VERSION ""

NS_ :

BS_:

BU_: VCU TBOX ACC GW LAS

BO_ 1107 ACC_NM: 8 ACC
 SG_ ACC_NMSourceAddress : 7|8@0+ (1,0) [0|255] ""  LAS

BO_ 1030 GW_NM: 8 GW
 SG_ GW_NMSourceAddress : 7|8@0+ (1,0) [0|255] ""  LAS

BO_ 1106 LAS_NM: 8 LAS
 SG_ LAS_NMSourceAddress : 7|8@0+ (1,0) [0|255] "" Vector__XXX

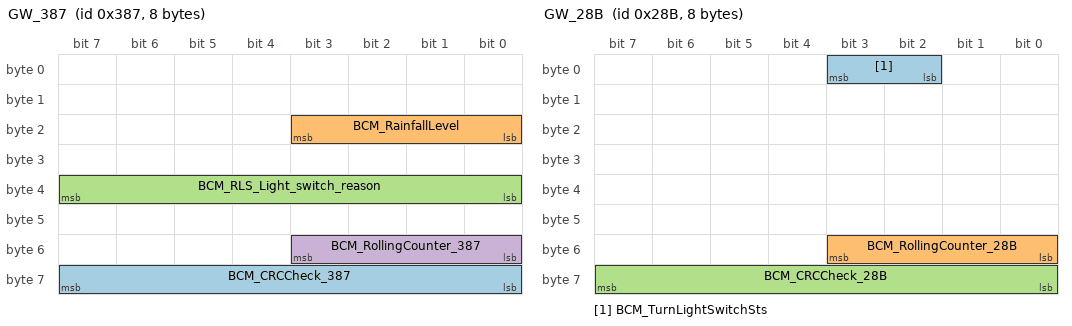
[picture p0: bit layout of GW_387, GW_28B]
BO_ 903 GW_387: 8 GW
 SG_ BCM_CRCCheck_387 : 63|8@0+ (1,0) [0|255] ""  LAS
 SG_ BCM_RainfallLevel : 19|4@0+ (1,0) [0|15] ""  LAS
 SG_ BCM_RLS_Light_switch_reason : 39|8@0+ (1,0) [0|255] ""  LAS
 SG_ BCM_RollingCounter_387 : 51|4@0+ (1,0) [0|15] ""  LAS

BO_ 651 GW_28B: 8 GW
 SG_ BCM_TurnLightSwitchSts : 3|2@0+ (1,0) [0|3] ""  LAS
 SG_ BCM_RollingCounter_28B : 51|4@0+ (1,0) [0|15] ""  LAS
 SG_ BCM_CRCCheck_28B : 63|8@0+ (1,0) [0|255] ""  LAS

BO_ 648 GW_288: 8 GW
 SG_ BcmAutHeadLiSts : 16|1@0+ (1,0) [0|1] ""  LAS
 SG_ BcmCrcChk288 : 63|8@0+ (1,0) [0|255] ""  LAS
 SG_ BcmCycCntr288 : 51|4@0+ (1,0) [0|15] ""  LAS
 SG_ BcmDrvrDoorSts : 23|1@0+ (1,0) [0|1] ""  LAS
 SG_ BcmFrntFogLmpSts : 3|2@0+ (1,0) [0|3] ""  LAS
 SG_ BcmFrntWiperSts : 47|2@0+ (1,0) [0|3] ""  LAS
 SG_ BcmHiBeamSts : 5|2@0+ (1,0) [0|3] ""  LAS
 SG_ BcmHoodSts : 18|1@0+ (1,0) [0|1] ""  LAS
 SG_ BcmLeReDoorSts : 21|1@0+ (1,0) [0|1] ""  LAS
 SG_ BcmLiSnsrFlt : 45|1@0+ (1,0) [0|1] ""  LAS
 SG_ BcmLoBeamSts : 7|2@0+ (1,0) [0|3] ""  LAS
 SG_ BcmPassDoorSts : 22|1@0+ (1,0) [0|1] ""  LAS
 SG_ BcmReFoglmpSts : 1|2@0+ (1,0) [0|3] ""  LAS
 SG_ BcmRiReDoorSts : 20|1@0+ (1,0) [0|1] ""  LAS
 SG_ BcmStsRainSnsr : 54|1@0+ (1,0) [0|1] ""  LAS
 SG_ BcmTurnIndcrLe : 15|2@0+ (1,0) [0|3] ""  LAS
 SG_ BcmTurnIndcrRi : 13|2@0+ (1,0) [0|3] ""  LAS
 SG_ BcmEmgyLiSts : 37|2@0+ (1,0) [0|3] ""  LAS

BO_ 1006 GW_3EE: 8 GW
 SG_ GW_SafCertSts : 7|2@0+ (1,0) [0|3] ""  LAS

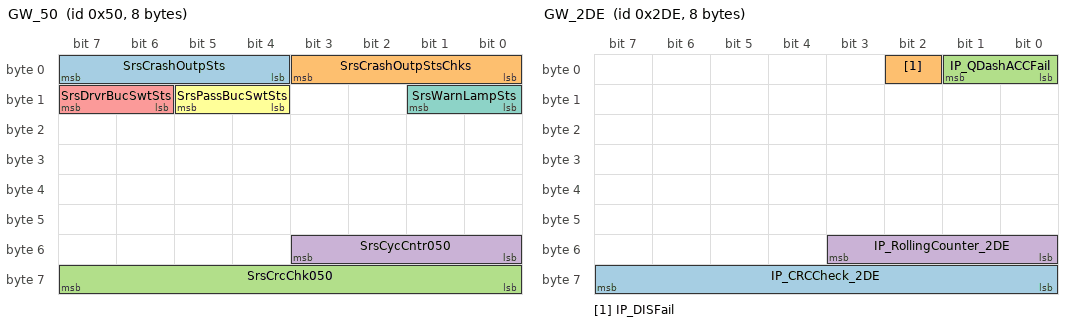
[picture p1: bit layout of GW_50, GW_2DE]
BO_ 80 GW_50: 8 GW
 SG_ SrsCrashOutpSts : 7|4@0+ (1,0) [0|15] ""  LAS
 SG_ SrsCrashOutpStsChks : 3|4@0+ (1,0) [0|15] ""  LAS
 SG_ SrsCrcChk050 : 63|8@0+ (1,0) [0|255] ""  LAS
 SG_ SrsCycCntr050 : 51|4@0+ (1,0) [0|15] ""  LAS
 SG_ SrsDrvrBucSwtSts : 15|2@0+ (1,0) [0|3] ""  LAS
 SG_ SrsPassBucSwtSts : 13|2@0+ (1,0) [0|3] ""  LAS
 SG_ SrsWarnLampSts : 9|2@0+ (1,0) [0|3] ""  LAS

BO_ 759 TBOX_2F7: 64 TBOX
 SG_ TboxLocalTiDate : 20|5@0+ (1,0) [0|31] "day"  LAS
 SG_ TboxLocalTiHr : 28|5@0+ (1,0) [0|31] "hour"  LAS
 SG_ TboxLocalTiMins : 37|6@0+ (1,0) [0|63] "minute"  LAS
 SG_ TboxLocalTiMth : 11|4@0+ (1,0) [0|15] "month"  LAS
 SG_ TboxLocalTiSec : 45|6@0+ (1,0) [0|63] "second"  LAS
 SG_ TboxLocalTiVld : 46|1@0+ (1,0) [0|1] ""  LAS
 SG_ TboxLocalTiYear : 7|8@0+ (1,2000) [2000|2255] "year"  LAS

BO_ 353 VCU_161: 64 VCU
 SG_ VcuSimnEpbSwtSts : 45|2@0+ (1,0) [0|3] ""  LAS
 SG_ VcuSimnEpbSwtStsVld : 46|1@0+ (1,0) [0|1] ""  LAS
 SG_ VCUAccPedShield : 7|1@0+ (1,0) [0|1] ""  LAS
 SG_ VCUShiftPostionValid : 2|1@0+ (1,0) [0|1] ""  LAS
 SG_ VcuAccrMod : 1|3@0+ (1,0) [0|7] ""  LAS
 SG_ VcuAccrPedlPosn : 14|10@0+ (0.1,0) [0|102.3] "%"  LAS
 SG_ VcuAccrPedlPosnVld : 20|1@0+ (1,0) [0|1] ""  LAS
 SG_ VcuCalcnAccrPedlPosn : 18|10@0+ (0.1,0) [0|102.3] "%"  LAS
 SG_ VcuCalcnAccrPedlPosnVld : 24|1@0+ (1,0) [0|1] ""  LAS
 SG_ VcuComFltSts : 39|2@0+ (1,0) [0|3] ""  LAS
 SG_ VcuEnyRecyclMod : 37|7@0+ (1,0) [0|127] ""  LAS
 SG_ VcuGearPosn : 65|3@0+ (1,0) [0|7] ""  LAS
 SG_ VcuOvrdModReq : 78|1@0+ (1,0) [0|1] ""  LAS
 SG_ VcuPtTqLimMax : 87|16@0+ (1,-32768) [-32768|32767] "Nm"  LAS
 SG_ VcuPtTqLimMaxVld : 77|1@0+ (1,0) [0|1] ""  LAS
 SG_ VcuPtTqLimMin : 103|16@0+ (1,-32768) [-32768|32767] "Nm"  LAS
 SG_ VcuPtTqLimMinVld : 76|1@0+ (1,0) [0|1] ""  LAS
 SG_ VcuPtTqReal : 135|16@0+ (1,-32768) [-32768|32767] "Nm"  LAS
 SG_ VcuPtTqRealVld : 75|1@0+ (1,0) [0|1] ""  LAS
 SG_ VcuPtTqReqAvl : 74|2@0+ (1,0) [0|3] ""  LAS
 SG_ VcuRdySts : 151|1@0+ (1,0) [0|1] ""  LAS
 SG_ VcuShiftLvlPosn : 119|4@0+ (1,0) [0|15] ""  LAS
 SG_ VcuVehGearPosnVld : 150|1@0+ (1,0) [0|1] ""  LAS
 SG_ VcuVehWhlReqTq : 159|16@0+ (1,-32768) [-32768|32767] "Nm"  LAS
 SG_ VcuVehWhlReqTqVld : 149|1@0+ (1,0) [0|1] ""  LAS
 SG_ VcuCrcChk161 : 503|16@0+ (1,0) [0|65535] ""  LAS
 SG_ VcuCycCntr161 : 491|4@0+ (1,0) [0|15] ""  LAS

BO_ 680 GW_2A8: 64 GW
 SG_ TmsAcEnvtlT : 39|8@0+ (0.5,-40) [-40|87.5] ""  LAS
 SG_ TmsAcEnvtlTVld : 432|1@0+ (1,0) [0|1] ""  LAS
 SG_ TmsFrntBlowMod : 186|3@0+ (1,0) [0|7] ""  LAS
 SG_ TmsActPwr : 18|11@0+ (0.01,0) [0|20.47] "kW"  LAS

BO_ 943 GW_3AF: 64 GW
 SG_ HU_AccidentProne : 149|2@0+ (1,0) [0|3] ""  LAS
 SG_ HU_AccidentProneDistance : 147|6@0+ (10,0) [0|600] "m"  LAS
 SG_ HU_BridgeDis : 163|6@0+ (10,0) [0|600] "m"  LAS
 SG_ HU_BridgeInfo : 165|2@0+ (1,0) [0|3] ""  LAS
 SG_ HU_CRCCheck_3AF : 255|8@0+ (1,0) [0|255] ""  LAS
 SG_ HU_CRCCheck_3BB : 319|8@0+ (1,0) [0|255] ""  LAS
 SG_ HU_CurveDistance : 229|6@0+ (10,0) [0|600] "m"  LAS
 SG_ HU_EnterCurveInfo : 220|2@0+ (1,0) [0|3] ""  LAS
 SG_ HU_EnterRampInfo : 215|2@0+ (1,0) [0|3] ""  LAS
 SG_ HU_IntervalVelocityDis : 139|6@0+ (10,0) [0|600] "m"  LAS
 SG_ HU_IntervalVelocityInfo : 141|2@0+ (1,0) [0|3] ""  LAS
 SG_ HU_LaneConfluence : 157|2@0+ (1,0) [0|3] ""  LAS
 SG_ HU_LaneConfluenceDis : 155|6@0+ (10,0) [0|600] "m"  LAS
 SG_ HU_LaneType_ID1 : 321|4@0+ (1,0) [0|15] ""  LAS
 SG_ HU_LaneType_ID2 : 333|4@0+ (1,0) [0|15] ""  LAS
 SG_ HU_LaneType_ID3 : 329|4@0+ (1,0) [0|15] ""  LAS
 SG_ HU_LaneType_ID4 : 341|4@0+ (1,0) [0|15] ""  LAS
 SG_ HU_LaneType_ID5 : 337|4@0+ (1,0) [0|15] ""  LAS
 SG_ HU_LaneType_ID6 : 349|4@0+ (1,0) [0|15] ""  LAS
 SG_ HU_NavCountryCode : 199|8@0+ (1,0) [0|255] ""  LAS
 SG_ HU_NavCurrentRoadType : 218|3@0+ (1,0) [0|7] ""  LAS
 SG_ HU_NavSpeedLimit : 207|8@0+ (1,0) [0|255] ""  LAS
 SG_ HU_NavSpeedLimitStatus : 211|2@0+ (1,0) [0|3] ""  LAS
 SG_ HU_NavSpeedLimitType : 231|2@0+ (1,0) [0|3] ""  LAS
 SG_ HU_NavSpeedLimitUnits : 213|2@0+ (1,0) [0|3] ""  LAS
 SG_ HU_NavStatus : 223|1@0+ (1,0) [0|1] ""  LAS
 SG_ HU_RampDistance : 239|10@0+ (10,0) [0|3000] "m"  LAS
 SG_ HU_RampInfo : 209|2@0+ (1,0) [0|3] ""  LAS
 SG_ HU_RollingCounter_3AF : 243|4@0+ (1,0) [0|15] ""  LAS
 SG_ HU_RollingCounter_3BB : 307|4@0+ (1,0) [0|15] ""  LAS
 SG_ HU_ServiceRoad : 183|2@0+ (1,0) [0|3] "m"  LAS
 SG_ HU_ServiceRoadDis : 327|6@0+ (10,0) [0|600] "m"  LAS
 SG_ HU_SlopeGradient : 265|10@0+ (0.1,-51.1) [-51.1|51.1] "%"  LAS
 SG_ HU_SlopeGradient_100m : 135|10@0+ (0.1,-51.1) [-51.1|51.1] "m"  LAS
 SG_ HU_SlopeGradient_10m : 71|10@0+ (0.1,-51.1) [-51.1|51.1] ""  LAS
 SG_ HU_SlopeGradient_20m : 77|10@0+ (0.1,-51.1) [-51.1|51.1] ""  LAS
 SG_ HU_SlopeGradient_30m : 83|10@0+ (0.1,-51.1) [-51.1|51.1] ""  LAS
 SG_ HU_SlopeGradient_40m : 89|10@0+ (0.1,-51.1) [-51.1|51.1] "m"  LAS
 SG_ HU_SlopeGradient_50m : 111|10@0+ (0.1,-51.1) [-51.1|51.1] ""  LAS
 SG_ HU_SlopeGradientFar : 281|10@0+ (0.1,-51.1) [-51.1|51.1] "%"  LAS
 SG_ HU_SpeedLimitDistance : 261|6@0+ (10,0) [0|600] "m"  LAS
 SG_ HU_WeatherType : 173|6@0+ (1,0) [0|63] ""  LAS

BO_ 1287 GW_507: 32 GW
 SG_ HU_AutoBrakeEnable : 131|1@0+ (1,0) [0|1] ""  LAS
 SG_ HU_CruiseControlSet : 135|3@0+ (1,0) [0|7] ""  LAS
 SG_ HU_FCWSetting : 165|3@0+ (1,0) [0|7] ""  LAS
 SG_ HU_HMAEnable : 12|1@0+ (1,0) [0|1] ""  LAS
 SG_ HU_IACCEnable : 29|2@0+ (1,0) [0|3] ""  LAS
 SG_ HU_LASModeSelection : 5|3@0+ (1,0) [0|7] ""  LAS
 SG_ HU_LASWarningModeSelection : 10|3@0+ (1,0) [0|7] ""  LAS
 SG_ HU_LDWShakeLev : 23|2@0+ (1,0) [0|3] ""  LAS
 SG_ HU_OverspeedSoundWarEnable : 31|2@0+ (1,0) [0|3] ""  LAS
 SG_ HU_OverspeedWarningEnable : 33|2@0+ (1,0) [0|3] ""  LAS
 SG_ HU_OverspeedWarningOffset : 38|5@0+ (1,-10) [-10|10] ""  LAS
 SG_ HU_TSRSwitch : 11|1@0+ (1,0) [0|1] ""  LAS
 SG_ HU_VC_CruiseControl : 138|3@0+ (1,0) [0|7] ""  LAS
 SG_ HU_VC_CruiseSetDistance : 142|3@0+ (1,0) [0|7] ""  LAS
 SG_ HU_VC_CruiseSetSpeed : 151|8@0+ (1,0) [0|255] ""  LAS

BO_ 964 GW_3C4: 64 GW
 SG_ HU_BranchInfo : 245|2@0+ (1,0) [0|3] ""  LAS
 SG_ HU_Byroad : 39|2@0+ (1,0) [0|3] ""  LAS
 SG_ HU_Construction_Info : 95|2@0+ (1,0) [0|3] ""  LAS
 SG_ HU_CRCCheck_3B8 : 63|8@0+ (1,0) [0|255] ""  LAS
 SG_ HU_CRCCheck_3C2 : 127|8@0+ (1,0) [0|255] ""  LAS
 SG_ HU_CRCCheck_3C4 : 191|8@0+ (1,0) [0|255] ""  LAS
 SG_ HU_CRCCheck_3C6 : 255|8@0+ (1,0) [0|255] ""  LAS
 SG_ HU_CRCCheck_3C7 : 319|8@0+ (1,0) [0|255] ""  LAS
 SG_ HU_EnterSlopeInfo : 5|2@0+ (1,0) [0|3] ""  LAS
 SG_ HU_EnterTunnelInfo : 3|2@0+ (1,0) [0|3] ""  LAS
 SG_ HU_FallingRockDi : 77|6@0+ (10,0) [0|600] "m"  LAS
 SG_ HU_FallingRockInfo : 79|2@0+ (1,0) [0|3] ""  LAS
 SG_ HU_ForwardRoadType : 69|3@0+ (1,0) [0|7] ""  LAS
 SG_ HU_Lane_Changtype : 129|2@0+ (1,0) [0|3] ""  LAS
 SG_ HU_LaneCnt : 66|3@0+ (1,0) [0|7] ""  LAS
 SG_ HU_MapDataUpdateStatus : 118|3@0+ (1,0) [0|7] ""  LAS
 SG_ HU_MapMatchStatus : 309|2@0+ (1,0) [0|3] ""  LAS
 SG_ HU_NavGuiganceStatus : 47|2@0+ (1,0) [0|3] ""  LAS
 SG_ HU_RampSide : 71|2@0+ (1,0) [0|3] ""  LAS
 SG_ HU_Road_TrafficFlow : 105|3@0+ (1,0) [0|7] ""  LAS
 SG_ HU_RoadCurvature : 1|10@0+ (1,0) [0|1023] ""  LAS
 SG_ HU_RoadCurvature_100m : 263|10@0+ (1,0) [0|1023] "1/m"  LAS
 SG_ HU_RoadCurvature_10m : 143|10@0+ (1,0) [0|1023] "1/m"  LAS
 SG_ HU_RoadCurvature_20m : 149|10@0+ (1,0) [0|1023] "1/m"  LAS
 SG_ HU_RoadCurvature_300m : 269|10@0+ (1,0) [0|1023] "1/m"  LAS
 SG_ HU_RoadCurvature_30m : 155|10@0+ (1,0) [0|1023] "1/m"  LAS
 SG_ HU_RoadCurvature_400m : 275|10@0+ (1,0) [0|1023] "1/m"  LAS
 SG_ HU_RoadCurvature_40m : 161|10@0+ (1,0) [0|1023] "1/m"  LAS
 SG_ HU_RoadCurvature_50m : 199|10@0+ (1,0) [0|1023] "1/m"  LAS
 SG_ HU_RoadCurvature_600m : 281|10@0+ (1,0) [0|1023] "1/m"  LAS
 SG_ HU_RoadCurvature_60m : 205|10@0+ (1,0) [0|1023] "1/m"  LAS
 SG_ HU_RoadCurvature_70m : 211|10@0+ (1,0) [0|1023] "1/m"  LAS
 SG_ HU_RoadCurvature_80m : 217|10@0+ (1,0) [0|1023] "1/m"  LAS
 SG_ HU_RoadCurvature_90m : 239|10@0+ (1,0) [0|1023] "1/m"  LAS
 SG_ HU_RoadCurvatureFar : 17|10@0+ (1,0) [0|1023] ""  LAS
 SG_ HU_RollingCounter_3B8 : 51|4@0+ (1,0) [0|15] ""  LAS
 SG_ HU_RollingCounter_3C2 : 115|4@0+ (1,0) [0|15] ""  LAS
 SG_ HU_RollingCounter_3C4 : 179|4@0+ (1,0) [0|15] ""  LAS
 SG_ HU_RollingCounter_3C6 : 243|4@0+ (1,0) [0|15] ""  LAS
 SG_ HU_RollingCounter_3C7 : 307|4@0+ (1,0) [0|15] ""  LAS
 SG_ HU_SlopeDistance : 45|6@0+ (10,0) [0|600] "m"  LAS
 SG_ HU_SlopeGradient_300m : 303|10@0+ (0.1,-51.1) [-51.1|51.1] "%"  LAS
 SG_ HU_To_Branch_Dis : 111|6@0+ (10,0) [0|600] "m"  LAS
 SG_ HU_To_Construction_Dis : 93|6@0+ (10,0) [0|600] "m"  LAS
 SG_ HU_To_NumchangeOfLanes_Dist : 135|6@0+ (10,0) [0|600] "m"  LAS
 SG_ HU_To_TrafficAccident_Dis : 101|6@0+ (10,0) [0|600] "m"  LAS
 SG_ HU_TollDis : 85|6@0+ (10,0) [0|600] "m"  LAS
 SG_ HU_TollInfo : 87|2@0+ (1,0) [0|3] ""  LAS
 SG_ HU_TrafficAccident_Info : 103|2@0+ (1,0) [0|3] ""  LAS
 SG_ HU_TunnelDistance : 23|6@0+ (10,0) [0|600] "m"  LAS
 SG_ HU_TunnelLength : 37|6@0+ (1,0) [0|63] "m"  LAS

BO_ 854 GW_356: 64 GW
 SG_ IMS_BrowOffsetValue : 95|4@0+ (1,0) [0|15] "cm"  LAS
 SG_ IMS_CRCCheck_356 : 63|8@0+ (1,0) [0|255] ""  LAS
 SG_ IMS_CRCCheck_360 : 127|8@0+ (1,0) [0|255] ""  LAS
 SG_ IMS_DistractionStatus : 7|2@0+ (1,0) [0|3] ""  LAS
 SG_ IMS_DriverEyeClosestatus : 27|3@0+ (1,0) [0|7] ""  LAS
 SG_ IMS_DriverEyeConfidence : 43|8@0+ (1,0) [0|255] "%"  LAS
 SG_ IMS_DriverEyeDetect : 29|2@0+ (1,0) [0|3] ""  LAS
 SG_ IMS_DriverEyesFovArea : 47|4@0+ (1,0) [0|15] ""  LAS
 SG_ IMS_DriverHeadDetect : 5|2@0+ (1,0) [0|3] ""  LAS
 SG_ IMS_DrowsinessStatus : 3|3@0+ (1,0) [0|7] ""  LAS
 SG_ IMS_EyeDetectSatus : 13|8@0+ (1,0) [0|100] "%"  LAS
 SG_ IMS_EyeGazeStatus : 21|8@0+ (1,-75) [-75|75] ""  LAS
 SG_ IMS_HeadDetectSts_Pitch : 71|8@0+ (1,-25) [-25|45] ""  LAS
 SG_ IMS_HeadDetectSts_Roll : 79|8@0+ (1,-45) [-45|45] ""  LAS
 SG_ IMS_HeadDetectSts_Yaw : 87|8@0+ (1,-75) [-75|75] ""  LAS
 SG_ IMS_IMSStatus : 0|3@0+ (1,0) [0|7] ""  LAS
 SG_ IMS_JawOffsetValue : 91|4@0+ (1,0) [0|15] "cm"  LAS
 SG_ IMS_PhoneCallSts : 24|1@0+ (1,0) [0|1] ""  LAS
 SG_ IMS_RollingCounter_356 : 51|4@0+ (1,0) [0|15] ""  LAS
 SG_ IMS_RollingCounter_360 : 115|4@0+ (1,0) [0|15] ""  LAS

BO_ 734 GW_2DE: 8 GW
 SG_ IP_CRCCheck_2DE : 63|8@0+ (1,0) [0|255] ""  LAS
 SG_ IP_DISFail : 2|1@0+ (1,0) [0|1] ""  LAS
 SG_ IP_QDashACCFail : 1|2@0+ (1,0) [0|3] ""  LAS
 SG_ IP_RollingCounter_2DE : 51|4@0+ (1,0) [0|15] ""  LAS

BO_ 722 GW_2D2: 64 GW
 SG_ CdcTotMilg : 399|24@0+ (0.1,0) [0|1677721.5] "Km"  LAS
 SG_ CdcCycCntr2D2 : 491|4@0+ (1,0) [0|15] ""  LAS
 SG_ CdcCycChk2D2 : 503|16@0+ (1,0) [0|65535] ""  LAS

BO_ 1302 GW_516: 32 GW
 SG_ HU_CurrentLocationValid : 7|1@0+ (1,0) [0|1] ""  LAS
 SG_ HU_CurrentLocationLongitude : 4|29@0+ (1E-006,-268.435455) [-180|180] "degree"  LAS
 SG_ HU_CurrentLocationLatitude : 35|28@0+ (1E-006,-134.217727) [-90|90] "degree"  LAS

BO_ 794 ACC_31A: 64 ACC
 SG_ ACC_Voiceinfo : 47|5@0+ (1,0) [0|31] ""  LAS
 SG_ ACC_RollingCounter_36D : 51|4@0+ (1,0) [0|15] ""  LAS
 SG_ ACC_CRCCheck_36D : 63|8@0+ (1,0) [0|255] ""  LAS
 SG_ ACC_LASModeSelectionStatus : 66|3@0+ (1,0) [0|7] ""  LAS
 SG_ ACC_LASWarningModeSelectionSts : 74|3@0+ (1,0) [0|7] ""  LAS
 SG_ ACC_IACCHWAEnable : 78|1@0+ (1,0) [0|1] ""  LAS
 SG_ ACC_RollingCounter_31A : 491|4@0+ (1,0) [0|15] ""  LAS
 SG_ ACC_CRCCheck_31A : 503|16@0+ (1,0) [0|65535] ""  LAS
 SG_ ACC_RollingCounter_30A : 115|4@0+ (1,0) [0|15] ""  LAS
 SG_ ACC_CRCCheck_30A : 127|8@0+ (1,0) [0|255] ""  LAS
 SG_ ACC_IACCHWAMode : 135|3@0+ (1,0) [0|7] ""  LAS
 SG_ ACC_DriverHandsOffStatus : 137|2@0+ (1,0) [0|3] ""  LAS
 SG_ ACC_IACCHWATextInfoForDriver : 143|5@0+ (1,0) [0|31] ""  LAS
 SG_ ACC_LatTakeoverReq : 132|2@0+ (1,0) [0|3] ""  LAS
 SG_ ACC_HostLaneLeftStatus : 83|4@0+ (1,0) [0|15] ""  LAS
 SG_ ACC_HostLaneRightStatus : 87|4@0+ (1,0) [0|15] ""  LAS
 SG_ ACC_LLaneMarkerType : 94|3@0+ (1,0) [0|7] ""  LAS
 SG_ ACC_RLaneMarkerType : 70|3@0+ (1,0) [0|7] ""  LAS

BO_ 580 ACC_244: 64 ACC
 SG_ ACC_ABAActive : 84|1@0+ (1,0) [0|1] ""  LAS
 SG_ ACC_ABAlevel : 86|2@0+ (1,0) [0|3] ""  LAS
 SG_ ACC_ACCMode : 54|3@0+ (1,0) [0|7] ""  LAS
 SG_ ACC_ACCTargetAcceleration : 7|8@0+ (0.05,-5) [-5|7.75] "m/s2"  LAS
 SG_ ACC_AccTrqReq : 89|15@0+ (1,-16384) [-16384|16383] "Nm"  LAS
 SG_ ACC_AccTrqReqActive : 106|1@0+ (1,0) [0|1] ""  LAS
 SG_ ACC_AEBActive : 87|1@0+ (1,0) [0|1] ""  LAS
 SG_ ACC_AEBCtrlType : 104|4@0+ (1,0) [0|15] ""  LAS
 SG_ ACC_AEBTargetDeceleration : 71|16@0+ (0.0005,-16) [-16|16] "m/s2"  LAS
 SG_ ACC_AEBVehilceHoldReq : 90|1@0+ (1,0) [0|1] ""  LAS
 SG_ ACC_AWBActive : 95|1@0+ (1,0) [0|1] ""  LAS
 SG_ ACC_AWBlevel : 83|4@0+ (1,0) [0|15] ""  LAS
 SG_ ACC_CDDActive : 44|1@0+ (1,0) [0|1] ""  LAS
 SG_ ACC_CRCCheck_24E : 63|8@0+ (1,0) [0|255] ""  LAS
 SG_ ACC_CRCCheck_25E : 127|8@0+ (1,0) [0|255] ""  LAS
 SG_ ACC_DecToStop : 31|1@0+ (1,0) [0|1] ""  LAS
 SG_ ACC_Driveoff_Request : 55|1@0+ (1,0) [0|1] ""  LAS
 SG_ ACC_EmergencyDataRrdReq : 23|2@0+ (1,0) [0|3] ""  LAS
 SG_ ACC_FCWActive : 93|1@0+ (1,0) [0|1] ""  LAS
 SG_ ACC_FCWPreWarning : 91|1@0+ (1,0) [0|1] ""  LAS
 SG_ ACC_LDWStatus : 9|2@0+ (1,0) [0|3] ""  LAS
 SG_ ACC_LDWVibrationWarningReq : 11|2@0+ (1,0) [0|3] ""  LAS
 SG_ ACC_LKAStatus : 13|2@0+ (1,0) [0|3] ""  LAS
 SG_ ACC_PrefillActive : 94|1@0+ (1,0) [0|1] ""  LAS
 SG_ ACC_RollingCounter_24E : 51|4@0+ (1,0) [0|15] ""  LAS
 SG_ ACC_RollingCounter_25E : 115|4@0+ (1,0) [0|15] ""  LAS
 SG_ ADS_Authernticator_244 : 463|56@0+ (1,0) [0|0] ""  LAS
 SG_ ADS_MesssageCounter_244 : 455|6@0+ (1,0) [0|63] ""  LAS
 SG_ ADS_ResetFlag_244 : 449|2@0+ (1,0) [0|3] ""  LAS
 SG_ ACC_FCWLatentWarning : 92|1@0+ (1,0) [0|1] ""  LAS

BO_ 775 ACC_307: 64 ACC
 SG_ ACC_ACCEPBrequest : 23|1@0+ (1,0) [0|1] ""  LAS
 SG_ ACC_ACCTargetLngRange : 71|9@0+ (0.5,-70) [-70|180] "m"  LAS
 SG_ ACC_ACCTargetType : 78|4@0+ (1,0) [0|15] ""  LAS
 SG_ ACC_CRCCheck_307 : 503|16@0+ (1,0) [0|65535] ""  LAS
 SG_ ACC_CRCCheck_322 : 127|8@0+ (1,0) [0|255] ""  LAS
 SG_ ACC_CRCCheck_344 : 191|8@0+ (1,0) [0|255] ""  LAS
 SG_ ACC_CRCCheck_35E : 63|8@0+ (1,0) [0|255] ""  LAS
 SG_ ACC_CRCCheck_35F : 255|8@0+ (1,0) [0|255] ""  LAS
 SG_ ACC_DistanceLevel : 22|3@0+ (1,0) [0|7] ""  LAS
 SG_ ACC_HostTargetDetection : 87|3@0+ (1,0) [0|7] ""  LAS
 SG_ ACC_LngTakeOverReq : 12|2@0+ (1,0) [0|3] ""  LAS
 SG_ ACC_ObjValid : 13|1@0+ (1,0) [0|1] ""  LAS
 SG_ ACC_SetSpeed : 6|8@0+ (1,0) [0|254] "Km/h"  LAS
 SG_ ACC_TextInfoForDriver : 84|5@0+ (1,0) [0|31] ""  LAS
 SG_ ACC_TimeGapSet : 18|3@0+ (1,0) [0|7] ""  LAS
 SG_ ACC_RollingCounter_307 : 491|4@0+ (1,0) [0|15] ""  LAS
 SG_ ACC_RollingCounter_322 : 115|4@0+ (1,0) [0|15] ""  LAS
 SG_ ACC_RollingCounter_344 : 179|4@0+ (1,0) [0|15] ""  LAS
 SG_ ACC_RollingCounter_35E : 51|4@0+ (1,0) [0|15] ""  LAS
 SG_ ACC_RollingCounter_35F : 243|4@0+ (1,0) [0|15] ""  LAS
 SG_ ACC_SaftyBelt_Tightened : 41|2@0+ (1,0) [0|3] ""  LAS
 SG_ ACC_SaftyBeltVibrationReq : 42|1@0+ (1,0) [0|1] ""  LAS

BO_ 786 ACC_312: 64 ACC
 SG_ ACC_ACCTargetID : 6|4@0+ (1,0) [0|15] ""  LAS
 SG_ ACC_LLaneDistanceFusion : 30|7@0+ (0.05,-1) [-1|5] "m"  LAS
 SG_ ACC_RLaneDistanceFusion : 38|7@0+ (0.05,-1) [-1|5] "m"  LAS
 SG_ ACC_RollingCounter_3E4 : 51|4@0+ (1,0) [0|15] ""  LAS
 SG_ ACC_CRCCheck_3E4 : 63|8@0+ (1,0) [0|255] ""  LAS
 SG_ ADS_RollingCounter_312 : 491|4@0+ (1,0) [0|15] ""  LAS
 SG_ ADS_CRCCheck_312 : 503|16@0+ (1,0) [0|65535] ""  LAS

BO_ 922 LAS_39A: 64 LAS
 SG_ LAS_TLAEnable : 194|1@0+ (1,0) [0|1] "" Vector__XXX
 SG_ LAS_TLAStatus : 193|2@0+ (1,0) [0|3] "" Vector__XXX
 SG_ LAS_TLAWarninglevel : 197|2@0+ (1,0) [0|3] "" Vector__XXX
 SG_ LAS_TLAObjectDetection_HostLane : 200|1@0+ (1,0) [0|1] "" Vector__XXX
 SG_ LAS_TLAObjectColour_HostLane : 204|2@0+ (1,0) [0|3] "" Vector__XXX
 SG_ LAS_TLAObjectType_HostLane : 212|3@0+ (1,0) [0|7] "" Vector__XXX
 SG_ LAS_TLAObjectStatus_HostLane : 199|2@0+ (1,0) [0|3] "" Vector__XXX
 SG_ LAS_TLAArrowDirection_HostLane : 215|3@0+ (1,0) [0|7] "" Vector__XXX
 SG_ LAS_TLAObjectDetection_LeftLane : 223|1@0+ (1,0) [0|1] "" Vector__XXX
 SG_ LAS_TLAObjectColour_LeftLane : 221|2@0+ (1,0) [0|3] "" Vector__XXX
 SG_ LAS_TLAObjectStatus_LeftLane : 245|2@0+ (1,0) [0|3] "" Vector__XXX
 SG_ LAS_TLAObjectType_LeftLane : 219|3@0+ (1,0) [0|7] "" Vector__XXX
 SG_ LAS_TLAArrowDirection_LeftLane : 216|3@0+ (1,0) [0|7] "" Vector__XXX
 SG_ LAS_TLAObjectDetection_RightLane : 227|1@0+ (1,0) [0|1] "" Vector__XXX
 SG_ LAS_TLAObjectColour_RightLane : 225|2@0+ (1,0) [0|3] "" Vector__XXX
 SG_ LAS_TLAObjectStatus_RightLane : 247|2@0+ (1,0) [0|3] "" Vector__XXX
 SG_ LAS_TLAObjectType_RightLane : 239|3@0+ (1,0) [0|7] "" Vector__XXX
 SG_ LAS_TLAArrowDirection_RightLane : 236|3@0+ (1,0) [0|7] "" Vector__XXX
 SG_ LAS_RollingCounter_37D : 243|4@0+ (1,0) [0|15] "" Vector__XXX
 SG_ LAS_CRCCheck_37D : 255|8@0+ (1,0) [0|255] "" Vector__XXX
 SG_ LAS_OverspeedVisualWarning : 5|1@0+ (1,0) [0|1] "" Vector__XXX
 SG_ LAS_OverspeedSoundWarning : 2|1@0+ (1,0) [0|1] "" Vector__XXX
 SG_ LAS_OverspeedWarningEnableStatus : 15|1@0+ (1,0) [0|1] "" Vector__XXX
 SG_ LAS_OverspeedWarningOffset : 14|5@0+ (1,-10) [-10|10] "km/h" Vector__XXX
 SG_ LAS_FrontCameraFailureStatus : 17|2@0+ (1,0) [0|3] "" Vector__XXX
 SG_ LAS_FrontCameraCalibrationStatus : 20|2@0+ (1,0) [0|3] "" Vector__XXX
 SG_ LAS_TSRStatus : 26|3@0+ (1,0) [0|7] "" Vector__XXX
 SG_ LAS_TSRHostSpdLimit : 39|8@0+ (1,0) [0|255] "" Vector__XXX
 SG_ LAS_TSRHostSpdLimitUnits : 41|2@0+ (1,0) [0|3] "" Vector__XXX
 SG_ LAS_HMAStatus : 44|2@0+ (1,0) [0|3] "" Vector__XXX
 SG_ LAS_HMALightDistribution : 8|1@0+ (1,0) [0|1] "" Vector__XXX
 SG_ LAS_HMAEnableStatus : 22|1@0+ (1,0) [0|1] "" Vector__XXX
 SG_ LAS_TSREnable : 30|1@0+ (1,0) [0|1] "" Vector__XXX
 SG_ LAS_OverspeedSoundWarningEnSt : 27|1@0+ (1,0) [0|1] "" Vector__XXX
 SG_ LAS_RollingCounter_332 : 51|4@0+ (1,0) [0|15] "" Vector__XXX
 SG_ LAS_CRCCheck_332 : 63|8@0+ (1,0) [0|255] "" Vector__XXX
 SG_ LAS_TSRProhibitionSign : 66|5@0+ (1,0) [0|31] "" Vector__XXX
 SG_ LAS_TSRWarningSign : 83|4@0+ (1,0) [0|15] "" Vector__XXX
 SG_ LAS_TSRMandatorySign : 70|4@0+ (1,0) [0|15] "" Vector__XXX
 SG_ LAS_TLACountDownTime_HostLane : 94|7@0+ (1,0) [0|127] "" Vector__XXX
 SG_ LAS_TLADistance_HostLane : 103|8@0+ (1,0) [0|255] "" Vector__XXX
 SG_ LAS_TLAStopLine_HostLane : 111|8@0+ (1,0) [0|255] "" Vector__XXX
 SG_ LAS_RollingCounter_3D4 : 115|4@0+ (1,0) [0|15] "" Vector__XXX
 SG_ LAS_CRCCheck_3D4 : 127|8@0+ (1,0) [0|255] "" Vector__XXX
 SG_ LAS_TSRLeftLaneSpdLimit : 135|8@0+ (1,0) [0|255] "" Vector__XXX
 SG_ LAS_TSRRightLaneSpdLimit : 143|8@0+ (1,0) [0|255] "" Vector__XXX
 SG_ LAS_RollingCounter_3C0 : 179|4@0+ (1,0) [0|15] "" Vector__XXX
 SG_ LAS_CRCCheck_3C0 : 191|8@0+ (1,0) [0|255] "" Vector__XXX
 SG_ LAS_TSRLeftLaneStatus : 47|3@0+ (1,0) [0|7] "" Vector__XXX
 SG_ LAS_TSRRightLaneStatus : 55|3@0+ (1,0) [0|7] "" Vector__XXX
 SG_ LAS_RollingCounter_39A : 491|4@0+ (1,0) [0|15] "" Vector__XXX
 SG_ LAS_CRCCheck_39A : 503|16@0+ (1,0) [0|65535] "" Vector__XXX

BO_ 898 ACC_382: 64 ACC
 SG_ ACC_CRCCheck_3E6 : 191|8@0+ (1,0) [0|255] ""  LAS
 SG_ ACC_RollingCounter_3E6 : 179|4@0+ (1,0) [0|15] ""  LAS
 SG_ ACC_RollingCounter_382 : 491|4@0+ (1,0) [0|15] ""  LAS
 SG_ ACC_CRCCheck_382 : 503|16@0+ (1,0) [0|65535] ""  LAS

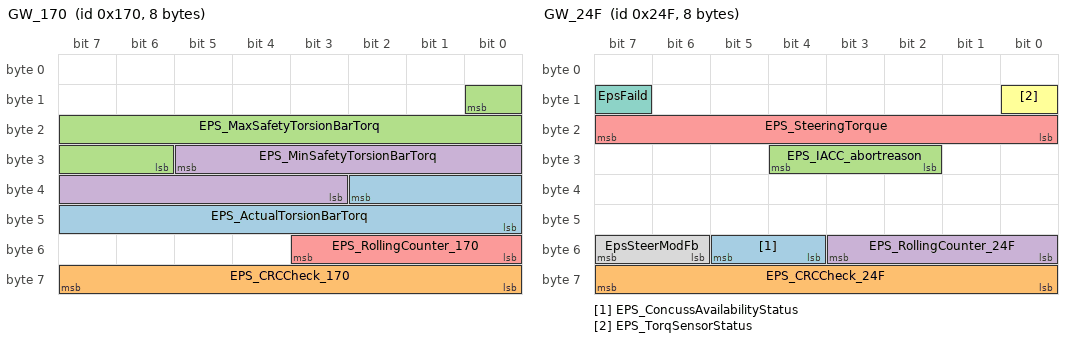
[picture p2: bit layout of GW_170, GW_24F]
BO_ 368 GW_170: 8 GW
 SG_ EPS_ActualTorsionBarTorq : 34|11@0+ (0.02,-20.48) [-20.48|20.46] "Nm"  LAS
 SG_ EPS_CRCCheck_170 : 63|8@0+ (1,0) [0|255] ""  LAS
 SG_ EPS_MaxSafetyTorsionBarTorq : 8|11@0+ (0.02,-20.48) [-20.48|20.46] "Nm"  LAS
 SG_ EPS_MinSafetyTorsionBarTorq : 29|11@0+ (0.02,-20.48) [-20.48|20.46] "Nm"  LAS
 SG_ EPS_RollingCounter_170 : 51|4@0+ (1,0) [0|15] ""  LAS

BO_ 591 GW_24F: 8 GW
 SG_ EPS_ConcussAvailabilityStatus : 53|2@0+ (1,0) [0|3] ""  LAS
 SG_ EPS_CRCCheck_24F : 63|8@0+ (1,0) [0|255] ""  LAS
 SG_ EPS_IACC_abortreason : 28|3@0+ (1,0) [0|7] ""  LAS
 SG_ EPS_RollingCounter_24F : 51|4@0+ (1,0) [0|15] ""  LAS
 SG_ EPS_SteeringTorque : 23|8@0+ (0.1794,-22.78) [-22.78|22.78] "Nm"  LAS
 SG_ EPS_TorqSensorStatus : 8|1@0+ (1,0) [0|1] ""  LAS
 SG_ EpsFaild : 15|1@0+ (1,0) [0|1] ""  LAS
 SG_ EpsSteerModFb : 55|2@0+ (1,0) [0|3] ""  LAS

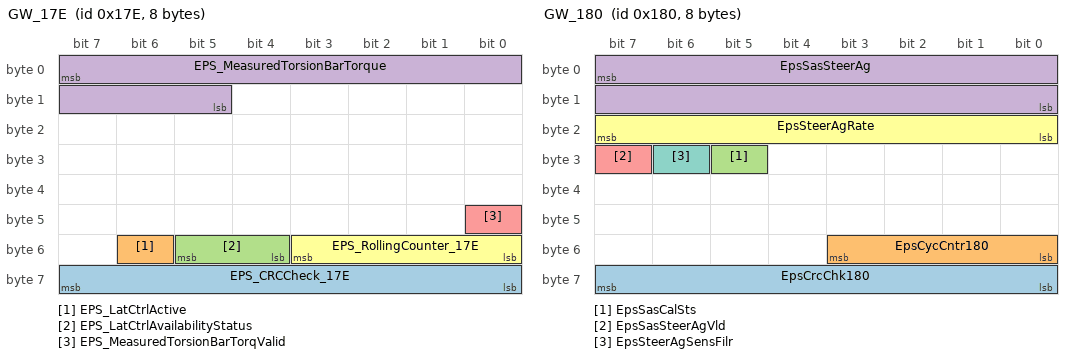
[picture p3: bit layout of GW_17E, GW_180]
BO_ 382 GW_17E: 8 GW
 SG_ EPS_CRCCheck_17E : 63|8@0+ (1,0) [0|255] ""  LAS
 SG_ EPS_LatCtrlActive : 54|1@0+ (1,0) [0|1] ""  LAS
 SG_ EPS_LatCtrlAvailabilityStatus : 53|2@0+ (1,0) [0|3] ""  LAS
 SG_ EPS_MeasuredTorsionBarTorque : 7|11@0+ (0.01,-10.23) [-10.23|10.23] "Nm"  LAS
 SG_ EPS_MeasuredTorsionBarTorqValid : 40|1@0+ (1,0) [0|1] ""  LAS
 SG_ EPS_RollingCounter_17E : 51|4@0+ (1,0) [0|15] ""  LAS

BO_ 384 GW_180: 8 GW
 SG_ EpsCrcChk180 : 63|8@0+ (1,0) [0|255] ""  LAS
 SG_ EpsCycCntr180 : 51|4@0+ (1,0) [0|15] ""  LAS
 SG_ EpsSasCalSts : 29|1@0+ (1,0) [0|1] ""  LAS
 SG_ EpsSasSteerAg : 7|16@0- (0.1,0) [-780|780] "degree"  LAS
 SG_ EpsSasSteerAgVld : 31|1@0+ (1,0) [0|1] ""  LAS
 SG_ EpsSteerAgRate : 23|8@0+ (4,0) [0|1016] "deg/s"  LAS
 SG_ EpsSteerAgSensFilr : 30|1@0+ (1,0) [0|1] ""  LAS

BO_ 706 GW_2C2: 64 GW
 SG_ IB_EPBrequest : 127|2@0+ (1,0) [0|3] ""  LAS
 SG_ IB_EPBrequestValid : 125|1@0+ (1,0) [0|1] ""  LAS
 SG_ IbBrkPedlStsGb : 7|8@0+ (1,0) [0|255] "%"  LAS
 SG_ IbBrkPedlStsGbVld : 15|2@0+ (1,0) [0|2] ""  LAS
 SG_ IbCrcChk2C2 : 503|16@0+ (1,0) [0|65535] ""  LAS
 SG_ IbCycCntr2C2 : 491|4@0+ (1,0) [0|15] ""  LAS

BO_ 962 GW_3C2: 64 GW
 SG_ EpbDriverReqParkBrakeDominant : 42|1@0+ (1,0) [0|1] ""  LAS
 SG_ EpbFailrSts : 1|2@0+ (1,0) [0|3] ""  LAS
 SG_ EpbLeAchievedClmpF : 11|5@0+ (1,0) [0|31] "KN"  LAS
 SG_ EpbRiAchievedClmpF : 22|5@0+ (1,0) [0|31] "KN"  LAS
 SG_ EpbSts : 7|3@0+ (1,0) [0|7] ""  LAS
 SG_ EspCrcChk3C2 : 503|16@0+ (1,0) [0|65535] ""  LAS
 SG_ EspCycCntr3C2 : 491|4@0+ (1,0) [0|15] ""  LAS
 SG_ EspEpbReqAvl : 28|1@0+ (1,0) [0|1] ""  LAS

BO_ 523 GW_20B: 48 GW
 SG_ ESP_ABAactive : 262|1@0+ (1,0) [0|1] ""  LAS
 SG_ ESP_ABAavailable : 261|1@0+ (1,0) [0|1] ""  LAS
 SG_ ESP_AEBAvailable : 258|1@0+ (1,0) [0|1] ""  LAS
 SG_ ESP_AEBdecActive : 257|1@0+ (1,0) [0|1] ""  LAS
 SG_ ESP_AWBactive : 256|1@0+ (1,0) [0|1] ""  LAS
 SG_ ESP_AWBavailable : 271|1@0+ (1,0) [0|1] ""  LAS
 SG_ ESP_BrakeForce : 263|1@0+ (1,0) [0|1] ""  LAS
 SG_ ESP_BrakeOverHeatBrakeDiscTemp : 270|1@0+ (1,0) [0|1] ""  LAS
 SG_ ESP_PrefillActive : 260|1@0+ (1,0) [0|1] ""  LAS
 SG_ ESP_PrefillAvailable : 259|1@0+ (1,0) [0|1] ""  LAS
 SG_ ESP_QDCACC : 279|2@0+ (1,0) [0|3] ""  LAS
 SG_ EspCrcChk20B : 375|16@0+ (1,0) [0|65535] ""  LAS
 SG_ EspCycCntr20B : 363|4@0+ (1,0) [0|15] ""  LAS
 SG_ ESP_CDD_Active : 269|1@0+ (1,0) [0|1] ""  LAS
 SG_ ESP_CDD_Available : 268|1@0+ (1,0) [0|1] ""  LAS

BO_ 450 GW_1C2: 64 GW
 SG_ EspCrcChk1C2 : 503|16@0+ (1,0) [0|65535] ""  LAS
 SG_ EspCycCntr1C2 : 491|4@0+ (1,0) [0|15] ""  LAS
 SG_ EspVehStandstill : 351|1@0+ (1,0) [0|1] ""  LAS
 SG_ EspLatAccel : 36|13@0+ (0.01,-32) [-32|49.91] "m/s2"  LAS
 SG_ EspLgtAccel : 85|13@0+ (0.01,-32) [-32|49.91] "m/s2"  LAS
 SG_ EspLgtAccelVld : 88|1@0+ (1,0) [0|1] ""  LAS
 SG_ WhlSpdReRiPls : 183|8@0+ (1,0) [0|255] ""  LAS
 SG_ WhlSpdReLePls : 199|8@0+ (1,0) [0|255] ""  LAS
 SG_ WhlSpdFrntRiPls : 191|8@0+ (1,0) [0|255] ""  LAS
 SG_ WhlSpdFrntLePls : 207|8@0+ (1,0) [0|255] ""  LAS
 SG_ WhlSpdRiFrntDir : 134|2@0+ (1,0) [0|3] ""  LAS
 SG_ WhlSpdLeFrntDir : 150|2@0+ (1,0) [0|3] ""  LAS
 SG_ WhlSpdRiReDir : 6|2@0+ (1,0) [0|3] ""  LAS
 SG_ WhlSpdLeReDir : 22|2@0+ (1,0) [0|3] ""  LAS
 SG_ EspYawAgSpd : 293|14@0+ (0.01,-81.91) [-81.91|81.92] "deg/s"  LAS
 SG_ EspYawAgSpdVld : 311|1@0+ (1,0) [0|1] ""  LAS
 SG_ EspReWhlIncTarTq : 335|16@0+ (1,-32768) [-32768|32767] "Nm"  LAS
 SG_ WhlSpdRiFrntDataVld : 135|1@0+ (1,0) [0|1] ""  LAS
 SG_ WhlSpdLeFrntDataVld : 151|1@0+ (1,0) [0|1] ""  LAS
 SG_ WhlSpdRiReDataVld : 7|1@0+ (1,0) [0|1] ""  LAS
 SG_ WhlSpdLeReDataVld : 23|1@0+ (1,0) [0|1] ""  LAS
 SG_ WhlSpdRiFrntData : 132|13@0+ (0.05625,0) [0|460.74375] "km/h"  LAS
 SG_ WhlSpdLeFrntData : 148|13@0+ (0.05625,0) [0|460.74375] "km/h"  LAS
 SG_ WhlSpdRiReData : 4|13@0+ (0.05625,0) [0|460.74375] "km/h"  LAS
 SG_ WhlSpdLeReData : 20|13@0+ (0.05625,0) [0|460.74375] "km/h"  LAS
 SG_ EspAutoHoldActvSts : 353|2@0+ (1,0) [0|3] ""  LAS
 SG_ EspMstCylBrkP : 71|12@0+ (0.1,0) [0|409.5] "Bar"  LAS
 SG_ EspMstCylBrkPVld : 75|1@0+ (1,0) [0|1] ""  LAS
 SG_ EspVdcActvSts : 414|1@0+ (1,0) [0|1] ""  LAS
 SG_ EspTcsActvSts : 52|1@0+ (1,0) [0|1] ""  LAS
 SG_ EspAbsActv : 72|1@0+ (1,0) [0|1] ""  LAS
 SG_ EspAbsFailr : 73|1@0+ (1,0) [0|1] ""  LAS
 SG_ EspFctOpenSts : 54|1@0+ (1,0) [0|1] ""  LAS
 SG_ EspTcsFailr : 53|1@0+ (1,0) [0|1] ""  LAS
 SG_ EspVehSpdVld : 101|1@0+ (1,0) [0|1] ""  LAS
 SG_ EspReWhlDecTarTqActv : 38|1@0+ (1,0) [0|1] ""  LAS
 SG_ EspReWhlIncTarTqActv : 37|1@0+ (1,0) [0|1] ""  LAS
 SG_ EspActvSts : 55|1@0+ (1,0) [0|1] ""  LAS
 SG_ MbRgnTarWhl : 423|16@0+ (1,-32768) [-32768|32766] "Nm"  LAS
 SG_ MbRgnTarWhlQlfr : 413|2@0+ (1,0) [0|3] ""  LAS
 SG_ EspReWhlDecTarTq : 271|16@0+ (1,-32768) [-32768|32767] "Nm"  LAS
 SG_ EspVehSpd : 100|13@0+ (0.05625,0) [0|460.74375] "km/h"  LAS
 SG_ EspLatAccelVld : 39|1@0+ (1,0) [0|1] ""  LAS

BO_ 466 GW_1D2: 64 GW
 SG_ EspMstCylBrkPIB : 13|10@0+ (0.3,-30) [-30|276.6] "Bar"  LAS
 SG_ EspMstCylBrkPVldIB : 19|2@0+ (1,0) [0|2] ""  LAS
 SG_ EspVirtMstCylTarBrkP : 25|10@0+ (0.25,0) [0|250] "Bar"  LAS
 SG_ EspVirtMstCylTarBrkPVld : 47|2@0+ (1,0) [0|2] ""  LAS
 SG_ EspVehSpdVldIB : 15|2@0+ (1,0) [0|2] ""  LAS
 SG_ EspEstimdWhlBrkPMax : 17|8@0+ (1,0) [0|250] "Bar"  LAS
 SG_ EspVehSpdIB : 7|8@0+ (1.44,0) [0|360] "km/h"  LAS
 SG_ EspCrcChk1D2 : 503|16@0+ (1,0) [0|65535] ""  LAS
 SG_ EspCycCntr1D2 : 491|4@0+ (1,0) [0|15] ""  LAS

BO_ 442 ACC_1BA: 32 ACC
 SG_ ACC_MotorTorqueMaxLimitRequest : 7|11@0+ (0.02,-20.48) [-20.48|20.44] "Nm"  LAS
 SG_ ACC_MotorTorqueMinLimitRequest : 12|11@0+ (0.02,-20.48) [-20.48|20.44] "Nm"  LAS
 SG_ ACC_LatAngReq : 17|14@0+ (0.1,-720) [-720|720] "degree"  LAS
 SG_ ACC_LatAngReqActive : 35|1@0+ (1,0) [0|1] ""  LAS
 SG_ ACC_RollingCounter_1C0 : 51|4@0+ (1,0) [0|15] ""  LAS
 SG_ ACC_CRCCheck_1C0 : 63|8@0+ (1,0) [0|255] ""  LAS
 SG_ ADS_MesssageCounter_1BA : 199|6@0+ (1,0) [0|63] ""  LAS
 SG_ ADS_ResetFlag_1BA : 193|2@0+ (1,0) [0|3] ""  LAS
 SG_ ADS_Authernticator_1BA : 207|56@0+ (1,0) [0|0] ""  LAS
 SG_ ADS_Reqmode : 87|3@0+ (1,0) [0|7] ""  LAS
 SG_ ADS_ErrorStatus : 72|1@0+ (1,0) [0|1] ""  LAS

BO_ 978 GW_3D2: 64 GW
 SG_ EpbDriverReqParkBrakeDominant : 42|1@0+ (1,0) [0|1] ""  LAS
 SG_ EpbFailrSts : 1|2@0+ (1,0) [0|3] ""  LAS
 SG_ EpbLeAchievedClmpF : 11|5@0+ (1,0) [0|31] "KN"  LAS
 SG_ EpbRiAchievedClmpF : 22|5@0+ (1,0) [0|31] "KN"  LAS
 SG_ EpbSts : 7|3@0+ (1,0) [0|7] ""  LAS
 SG_ EspCrcChk3D2 : 503|16@0+ (1,0) [0|65535] ""  LAS
 SG_ EspCycCntr3D2 : 491|4@0+ (1,0) [0|15] ""  LAS
 SG_ EspEpbReqAvl : 28|1@0+ (1,0) [0|1] ""  LAS

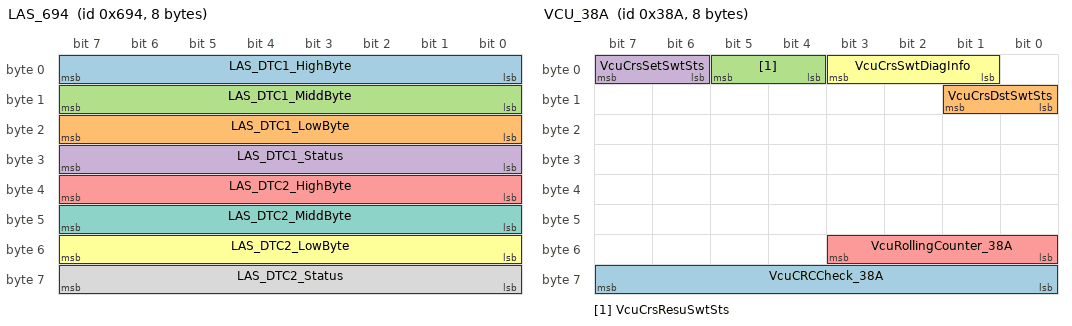
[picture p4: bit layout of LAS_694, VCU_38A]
BO_ 1684 LAS_694: 8 LAS
 SG_ LAS_DTC1_HighByte : 7|8@0+ (1,0) [0|255] "" Vector__XXX
 SG_ LAS_DTC1_LowByte : 23|8@0+ (1,0) [0|255] "" Vector__XXX
 SG_ LAS_DTC1_MiddByte : 15|8@0+ (1,0) [0|255] "" Vector__XXX
 SG_ LAS_DTC1_Status : 31|8@0+ (1,0) [0|255] "" Vector__XXX
 SG_ LAS_DTC2_HighByte : 39|8@0+ (1,0) [0|255] "" Vector__XXX
 SG_ LAS_DTC2_LowByte : 55|8@0+ (1,0) [0|255] "" Vector__XXX
 SG_ LAS_DTC2_MiddByte : 47|8@0+ (1,0) [0|255] "" Vector__XXX
 SG_ LAS_DTC2_Status : 63|8@0+ (1,0) [0|255] "" Vector__XXX

BO_ 676 GW_2A4: 64 GW
 SG_ LCDAR_CRCCheck_2AF : 63|8@0+ (1,0) [0|255] ""  LAS
 SG_ LCDAR_ELK_oAlert : 25|2@0+ (1,0) [0|3] ""  LAS
 SG_ LCDAR_ELK_oStatus : 27|2@0+ (1,0) [0|3] ""  LAS
 SG_ LCDAR_Left_ELK_oAlert : 29|2@0+ (1,0) [0|3] ""  LAS
 SG_ LCDAR_Left_RCTAAlert : 1|2@0+ (1,0) [0|3] ""  LAS
 SG_ LCDAR_RCTBActive : 19|1@0+ (1,0) [0|1] ""  LAS
 SG_ LCDAR_RCTBEnable : 18|1@0+ (1,0) [0|1] ""  LAS
 SG_ LCDAR_RCTBTargetDecel : 39|16@0+ (0.0005,-16) [-16|16] "m/s2"  LAS
 SG_ LCDAR_RollingCounter_2AF : 51|4@0+ (1,0) [0|15] ""  LAS
 SG_ LCDAR_SystemStatus : 12|3@0+ (1,0) [0|7] ""  LAS
 SG_ RRC_CRCCheck_2A4 : 503|16@0+ (1,0) [0|65535] ""  LAS
 SG_ RRC_RollingCounter_2A4 : 491|4@0+ (1,0) [0|15] ""  LAS

BO_ 906 VCU_38A: 8 VCU
 SG_ VcuCRCCheck_38A : 63|8@0+ (1,0) [0|255] ""  LAS
 SG_ VcuCrsDstSwtSts : 9|2@0+ (1,0) [0|3] ""  LAS
 SG_ VcuCrsResuSwtSts : 5|2@0+ (1,0) [0|3] ""  LAS
 SG_ VcuCrsSetSwtSts : 7|2@0+ (1,0) [0|3] ""  LAS
 SG_ VcuRollingCounter_38A : 51|4@0+ (1,0) [0|15] ""  LAS
 SG_ VcuCrsSwtDiagInfo : 3|3@0+ (1,0) [0|7] ""  LAS

BO_ 957 GW_3BD: 64 GW
 SG_ HU_CSLAEnable : 7|2@0+ (1,0) [0|3] ""  LAS
 SG_ HU_ELKEnable : 1|2@0+ (1,0) [0|3] ""  LAS
 SG_ HU_TLAEnable : 9|2@0+ (1,0) [0|3] ""  LAS

BO_ 888 ACC_378: 32 ACC
 SG_ ACC_LaneQuality : 6|6@0+ (0.015625,0) [0|0.984375] ""  LAS
 SG_ ACC_LaneEquationC1 : 9|12@0+ (0.00048828125,-1) [-1|0.9990234375] "rad"  LAS
 SG_ ACC_LaneEquationC2 : 29|12@0+ (1.52587890625E-005,-0.0312347412109375) [-0.0312347412109375|0.0312347412109375] ""  LAS
 SG_ ACC_LaneEquationC3 : 33|12@0+ (4.76837158203125E-007,-0.000976085662841797) [-0.000976085662841797|0.000976085662841797] ""  LAS
 SG_ ACC_LaneEquationStatus : 53|2@0+ (1,0) [0|3] ""  LAS

BO_ 685 GW_2AD: 64 GW
 SG_ LCDAL_SystemStatus : 6|3@0+ (1,0) [0|7] ""  LAS

BO_ 701 GW_2BD: 64 GW
 SG_ RRC_OBJ1_Track_ID : 20|7@0+ (1,0) [0|127] ""  LAS
 SG_ RRC_OBJ1_Type : 7|3@0+ (1,0) [0|7] ""  LAS
 SG_ RRC_OBJ1_Width : 15|11@0+ (0.01,0) [0|12] "m"  LAS
 SG_ RRC_OBJ1_Length : 29|9@0+ (0.05,0) [0|25.5] "m"  LAS
 SG_ RRC_OBJ1_HeadingAngle : 35|10@0+ (0.01,-3.14) [-3.14|3.14] "rad"  LAS
 SG_ RRC_OBJ1_Dy : 41|11@0+ (0.125,-128) [-128|127.875] "m"  LAS
 SG_ RRC_OBJ1_Dx : 62|13@0+ (0.0625,-256) [-256|255.9375] "m"  LAS
 SG_ RRC_OBJ1_Vy : 65|10@0+ (0.125,-64) [-64|63.875] "m/s"  LAS
 SG_ RRC_OBJ1_Vx : 87|12@0+ (0.0625,-128) [-128|127.9375] "m/s"  LAS
 SG_ RRC_OBJ1_Ay : 91|10@0+ (0.03125,-16) [-16|15.96875] "m/s2"  LAS
 SG_ RRC_OBJ1_Ax : 111|9@0+ (0.0625,-16) [-16|15.9375] "m/s2"  LAS
 SG_ RRC_OBJ1_Location : 97|2@0+ (1,0) [0|3] ""  LAS
 SG_ RRC_OBJ1_ExistProb : 116|6@0+ (2,0) [0|100] "%"  LAS
 SG_ RRC_OBJ1_Measured : 118|2@0+ (1,0) [0|3] ""  LAS
 SG_ RRC_OBJ1_ObstacleProb : 126|6@0+ (2,0) [0|100] "%"  LAS
 SG_ RRC_OBJ2_Track_ID : 143|7@0+ (1,0) [0|127] ""  LAS
 SG_ RRC_OBJ2_Type : 130|3@0+ (1,0) [0|7] ""  LAS
 SG_ RRC_OBJ2_Width : 136|11@0+ (0.01,0) [0|12] "m"  LAS
 SG_ RRC_OBJ2_Length : 157|9@0+ (0.05,0) [0|25.5] "m"  LAS
 SG_ RRC_OBJ2_HeadingAngle : 164|10@0+ (0.01,-3.14) [-3.14|3.14] "rad"  LAS
 SG_ RRC_OBJ2_Dy : 170|11@0+ (0.125,-128) [-128|127.875] "m"  LAS
 SG_ RRC_OBJ2_Dx : 191|13@0+ (0.0625,-256) [-256|255.9375] "m"  LAS
 SG_ RRC_OBJ2_Vy : 194|10@0+ (0.125,-64) [-64|63.875] "m/s"  LAS
 SG_ RRC_OBJ2_Vx : 223|12@0+ (0.0625,-128) [-128|127.9375] "m/s"  LAS
 SG_ RRC_OBJ2_Ay : 227|10@0+ (0.03125,-16) [-16|15.96875] "m/s2"  LAS
 SG_ RRC_OBJ2_Ax : 200|9@0+ (0.0625,-16) [-16|15.9375] "m/s2"  LAS
 SG_ RRC_OBJ2_Location : 233|2@0+ (1,0) [0|3] ""  LAS
 SG_ RRC_OBJ2_ExistProb : 247|6@0+ (2,0) [0|100] "%"  LAS
 SG_ RRC_OBJ2_Measured : 241|2@0+ (1,0) [0|3] ""  LAS
 SG_ RRC_OBJ2_ObstacleProb : 255|6@0+ (2,0) [0|100] "%"  LAS
 SG_ RRC_OBJ3_Track_ID : 262|7@0+ (1,0) [0|127] ""  LAS
 SG_ RRC_OBJ3_Type : 249|3@0+ (1,0) [0|7] ""  LAS
 SG_ RRC_OBJ3_Width : 271|11@0+ (0.01,0) [0|12] "m"  LAS
 SG_ RRC_OBJ3_Length : 284|9@0+ (0.05,0) [0|25.5] "m"  LAS
 SG_ RRC_OBJ3_HeadingAngle : 291|10@0+ (0.01,-3.14) [-3.14|3.14] "rad"  LAS
 SG_ RRC_OBJ3_Dy : 297|11@0+ (0.125,-128) [-128|127.875] "m"  LAS
 SG_ RRC_OBJ3_Dx : 318|13@0+ (0.0625,-256) [-256|255.9375] "m"  LAS
 SG_ RRC_OBJ3_Vy : 321|10@0+ (0.125,-64) [-64|63.875] "m/s"  LAS
 SG_ RRC_OBJ3_Vx : 343|12@0+ (0.0625,-128) [-128|127.9375] "m/s"  LAS
 SG_ RRC_OBJ3_Ay : 347|10@0+ (0.03125,-16) [-16|15.96875] "m/s2"  LAS
 SG_ RRC_OBJ3_Ax : 367|9@0+ (0.0625,-16) [-16|15.9375] "m/s2"  LAS
 SG_ RRC_OBJ3_Location : 353|2@0+ (1,0) [0|3] ""  LAS
 SG_ RRC_OBJ3_ExistProb : 372|6@0+ (2,0) [0|100] "%"  LAS
 SG_ RRC_OBJ3_Measured : 374|2@0+ (1,0) [0|3] ""  LAS
 SG_ RRC_OBJ3_ObstacleProb : 382|6@0+ (2,0) [0|100] "%"  LAS
 SG_ RRC_OBJ4_Track_ID : 376|7@0+ (1,0) [0|127] ""  LAS
 SG_ RRC_OBJ4_Type : 419|3@0+ (1,0) [0|7] ""  LAS
 SG_ RRC_OBJ4_Width : 407|11@0+ (0.01,0) [0|12] "m"  LAS
 SG_ RRC_OBJ4_Length : 412|9@0+ (0.05,0) [0|25.5] "m"  LAS
 SG_ RRC_OBJ4_HeadingAngle : 385|10@0+ (0.01,-3.14) [-3.14|3.14] "rad"  LAS
 SG_ RRC_OBJ4_Dy : 487|11@0+ (0.125,-128) [-128|127.875] "m"  LAS
 SG_ RRC_OBJ4_Dx : 439|13@0+ (0.0625,-256) [-256|255.9375] "m"  LAS
 SG_ RRC_OBJ4_Vy : 441|10@0+ (0.125,-64) [-64|63.875] "m/s"  LAS
 SG_ RRC_OBJ4_Vx : 463|12@0+ (0.0625,-128) [-128|127.9375] "m/s"  LAS
 SG_ RRC_OBJ4_Ay : 467|10@0+ (0.03125,-16) [-16|15.96875] "m/s2"  LAS
 SG_ RRC_OBJ4_Ax : 416|9@0+ (0.0625,-16) [-16|15.9375] "m/s2"  LAS
 SG_ RRC_OBJ4_Location : 473|2@0+ (1,0) [0|3] ""  LAS
 SG_ RRC_OBJ4_ExistProb : 120|6@0+ (2,0) [0|100] "%"  LAS
 SG_ RRC_OBJ4_Measured : 4|2@0+ (1,0) [0|3] ""  LAS
 SG_ RRC_OBJ4_ObstacleProb : 274|6@0+ (2,0) [0|100] "%"  LAS
 SG_ RRC_CRCCheck_2BD : 503|16@0+ (1,0) [0|65535] ""  LAS
 SG_ RRC_RollingCounter_2BD : 491|4@0+ (1,0) [0|15] ""  LAS

BO_ 712 GW_2C8: 64 GW
 SG_ RRC_OBJ1_Height : 342|9@0+ (0.01,0) [0|5.11] "m"  LAS
 SG_ RRC_OBJ2_Height : 270|9@0+ (0.01,0) [0|5.11] "m"  LAS
 SG_ RRC_OBJ3_Height : 277|9@0+ (0.01,0) [0|5.11] "m"  LAS
 SG_ RRC_OBJ4_Height : 284|9@0+ (0.01,0) [0|5.11] "m"  LAS
 SG_ RRC_OBJ5_Track_ID : 20|7@0+ (1,0) [0|127] ""  LAS
 SG_ RRC_OBJ5_Type : 7|3@0+ (1,0) [0|7] ""  LAS
 SG_ RRC_OBJ5_Width : 15|11@0+ (0.01,0) [0|12] "m"  LAS
 SG_ RRC_OBJ5_Height : 291|9@0+ (0.01,0) [0|5.11] "m"  LAS
 SG_ RRC_OBJ5_Length : 29|9@0+ (0.05,0) [0|25.5] "m"  LAS
 SG_ RRC_OBJ5_HeadingAngle : 35|10@0+ (0.01,-3.14) [-3.14|3.14] "rad"  LAS
 SG_ RRC_OBJ5_Dy : 41|11@0+ (0.125,-128) [-128|127.875] "m"  LAS
 SG_ RRC_OBJ5_Dx : 62|13@0+ (0.0625,-256) [-256|255.9375] "m"  LAS
 SG_ RRC_OBJ5_Vy : 65|10@0+ (0.125,-64) [-64|63.875] "m/s"  LAS
 SG_ RRC_OBJ5_Vx : 87|12@0+ (0.0625,-128) [-128|127.9375] "m/s"  LAS
 SG_ RRC_OBJ5_Ay : 91|10@0+ (0.03125,-16) [-16|15.96875] "m/s2"  LAS
 SG_ RRC_OBJ5_Ax : 111|9@0+ (0.0625,-16) [-16|15.9375] "m/s2"  LAS
 SG_ RRC_OBJ5_Location : 97|2@0+ (1,0) [0|3] ""  LAS
 SG_ RRC_OBJ5_ExistProb : 116|6@0+ (2,0) [0|100] "%"  LAS
 SG_ RRC_OBJ5_Measured : 118|2@0+ (1,0) [0|3] ""  LAS
 SG_ RRC_OBJ5_ObstacleProb : 126|6@0+ (2,0) [0|100] "%"  LAS
 SG_ RRC_OBJ6_Height : 298|9@0+ (0.01,0) [0|5.11] "m"  LAS
 SG_ RRC_OBJ7_Height : 305|9@0+ (0.01,0) [0|5.11] "m"  LAS
 SG_ RRC_OBJ8_Height : 312|9@0+ (0.01,0) [0|5.11] "m"  LAS
 SG_ RRC_OBJ9_Height : 335|9@0+ (0.01,0) [0|5.11] "m"  LAS
 SG_ RRC_OBJ10_Track_ID : 148|7@0+ (1,0) [0|127] ""  LAS
 SG_ RRC_OBJ10_Type : 120|3@0+ (1,0) [0|7] ""  LAS
 SG_ RRC_OBJ10_Width : 143|11@0+ (0.01,0) [0|12] "m"  LAS
 SG_ RRC_OBJ10_Height : 183|9@0+ (0.01,0) [0|5.11] "m"  LAS
 SG_ RRC_OBJ10_Length : 157|9@0+ (0.05,0) [0|25.5] "m"  LAS
 SG_ RRC_OBJ10_HeadingAngle : 248|10@0+ (0.01,-3.14) [-3.14|3.14] "rad"  LAS
 SG_ RRC_OBJ10_Dy : 164|11@0+ (0.125,-128) [-128|127.875] "m"  LAS
 SG_ RRC_OBJ10_Dx : 190|13@0+ (0.0625,-256) [-256|255.9375] "m"  LAS
 SG_ RRC_OBJ10_Vy : 193|10@0+ (0.125,-64) [-64|63.875] "m/s"  LAS
 SG_ RRC_OBJ10_Vx : 215|12@0+ (0.0625,-128) [-128|127.9375] "m/s"  LAS
 SG_ RRC_OBJ10_Ay : 219|10@0+ (0.03125,-16) [-16|15.96875] "m/s2"  LAS
 SG_ RRC_OBJ10_Ax : 239|9@0+ (0.0625,-16) [-16|15.9375] "m/s2"  LAS
 SG_ RRC_OBJ10_Location : 225|2@0+ (1,0) [0|3] ""  LAS
 SG_ RRC_OBJ10_ExistProb : 246|6@0+ (2,0) [0|100] "%"  LAS
 SG_ RRC_OBJ10_Measured : 169|2@0+ (1,0) [0|3] ""  LAS
 SG_ RRC_OBJ10_ObstacleProb : 133|6@0+ (2,0) [0|100] "%"  LAS
 SG_ RRC_ObjDelay : 240|8@0+ (1,0) [0|255] "ms"  LAS
 SG_ RRC_CRCCheck_2C8 : 503|16@0+ (1,0) [0|65535] ""  LAS
 SG_ RRC_RollingCounter_2C8 : 491|4@0+ (1,0) [0|15] ""  LAS
 SG_ RRC_TiStamp : 391|32@0+ (0.0001,0) [0|429496.7295] "s"  LAS
 SG_ RRC_TiBas : 423|1@0+ (1,0) [0|1] "-"  LAS
 SG_ RRC_TiLeap : 422|1@0+ (1,0) [0|1] "-"  LAS
 SG_ RRC_TiOut : 421|1@0+ (1,0) [0|1] "-"  LAS

BO_ 703 GW_2BF: 64 GW
 SG_ RRC_OBJ6_Track_ID : 20|7@0+ (1,0) [0|127] ""  LAS
 SG_ RRC_OBJ6_Type : 7|3@0+ (1,0) [0|7] ""  LAS
 SG_ RRC_OBJ6_Width : 15|11@0+ (0.01,0) [0|12] "m"  LAS
 SG_ RRC_OBJ6_Length : 29|9@0+ (0.05,0) [0|25.5] "m"  LAS
 SG_ RRC_OBJ6_HeadingAngle : 35|10@0+ (0.01,-3.14) [-3.14|3.14] "rad"  LAS
 SG_ RRC_OBJ6_Dy : 41|11@0+ (0.125,-128) [-128|127.875] "m"  LAS
 SG_ RRC_OBJ6_Dx : 62|13@0+ (0.0625,-256) [-256|255.9375] "m"  LAS
 SG_ RRC_OBJ6_Vy : 65|10@0+ (0.125,-64) [-64|63.875] "m/s"  LAS
 SG_ RRC_OBJ6_Vx : 87|12@0+ (0.0625,-128) [-128|127.9375] "m/s"  LAS
 SG_ RRC_OBJ6_Ay : 91|10@0+ (0.03125,-16) [-16|15.96875] "m/s2"  LAS
 SG_ RRC_OBJ6_Ax : 111|9@0+ (0.0625,-16) [-16|15.9375] "m/s2"  LAS
 SG_ RRC_OBJ6_Location : 97|2@0+ (1,0) [0|3] ""  LAS
 SG_ RRC_OBJ6_ExistProb : 116|6@0+ (2,0) [0|100] "%"  LAS
 SG_ RRC_OBJ6_Measured : 118|2@0+ (1,0) [0|3] ""  LAS
 SG_ RRC_OBJ6_ObstacleProb : 126|6@0+ (2,0) [0|100] "%"  LAS
 SG_ RRC_OBJ7_Track_ID : 143|7@0+ (1,0) [0|127] ""  LAS
 SG_ RRC_OBJ7_Type : 130|3@0+ (1,0) [0|7] ""  LAS
 SG_ RRC_OBJ7_Width : 136|11@0+ (0.01,0) [0|12] "m"  LAS
 SG_ RRC_OBJ7_Length : 157|9@0+ (0.05,0) [0|25.5] "m"  LAS
 SG_ RRC_OBJ7_HeadingAngle : 164|10@0+ (0.01,-3.14) [-3.14|3.14] "rad"  LAS
 SG_ RRC_OBJ7_Dy : 170|11@0+ (0.125,-128) [-128|127.875] "m"  LAS
 SG_ RRC_OBJ7_Dx : 191|13@0+ (0.0625,-256) [-256|255.9375] "m"  LAS
 SG_ RRC_OBJ7_Vy : 194|10@0+ (0.125,-64) [-64|63.875] "m/s"  LAS
 SG_ RRC_OBJ7_Vx : 223|12@0+ (0.0625,-128) [-128|127.9375] "m/s"  LAS
 SG_ RRC_OBJ7_Ay : 227|10@0+ (0.03125,-16) [-16|15.96875] "m/s2"  LAS
 SG_ RRC_OBJ7_Ax : 200|9@0+ (0.0625,-16) [-16|15.9375] "m/s2"  LAS
 SG_ RRC_OBJ7_Location : 233|2@0+ (1,0) [0|3] ""  LAS
 SG_ RRC_OBJ7_ExistProb : 247|6@0+ (2,0) [0|100] "%"  LAS
 SG_ RRC_OBJ7_Measured : 241|2@0+ (1,0) [0|3] ""  LAS
 SG_ RRC_OBJ7_ObstacleProb : 255|6@0+ (2,0) [0|100] "%"  LAS
 SG_ RRC_OBJ8_Track_ID : 262|7@0+ (1,0) [0|127] ""  LAS
 SG_ RRC_OBJ8_Type : 249|3@0+ (1,0) [0|7] ""  LAS
 SG_ RRC_OBJ8_Width : 271|11@0+ (0.01,0) [0|12] "m"  LAS
 SG_ RRC_OBJ8_Length : 284|9@0+ (0.05,0) [0|25.5] "m"  LAS
 SG_ RRC_OBJ8_HeadingAngle : 291|10@0+ (0.01,-3.14) [-3.14|3.14] "rad"  LAS
 SG_ RRC_OBJ8_Dy : 297|11@0+ (0.125,-128) [-128|127.875] "m"  LAS
 SG_ RRC_OBJ8_Dx : 318|13@0+ (0.0625,-256) [-256|255.9375] "m"  LAS
 SG_ RRC_OBJ8_Vy : 321|10@0+ (0.125,-64) [-64|63.875] "m/s"  LAS
 SG_ RRC_OBJ8_Vx : 343|12@0+ (0.0625,-128) [-128|127.9375] "m/s"  LAS
 SG_ RRC_OBJ8_Ay : 347|10@0+ (0.03125,-16) [-16|15.96875] "m/s2"  LAS
 SG_ RRC_OBJ8_Ax : 367|9@0+ (0.0625,-16) [-16|15.9375] "m/s2"  LAS
 SG_ RRC_OBJ8_Location : 353|2@0+ (1,0) [0|3] ""  LAS
 SG_ RRC_OBJ8_ExistProb : 372|6@0+ (2,0) [0|100] "%"  LAS
 SG_ RRC_OBJ8_Measured : 374|2@0+ (1,0) [0|3] ""  LAS
 SG_ RRC_OBJ8_ObstacleProb : 382|6@0+ (2,0) [0|100] "%"  LAS
 SG_ RRC_OBJ9_Track_ID : 376|7@0+ (1,0) [0|127] ""  LAS
 SG_ RRC_OBJ9_Type : 419|3@0+ (1,0) [0|7] ""  LAS
 SG_ RRC_OBJ9_Width : 407|11@0+ (0.01,0) [0|12] "m"  LAS
 SG_ RRC_OBJ9_Length : 412|9@0+ (0.05,0) [0|25.5] "m"  LAS
 SG_ RRC_OBJ9_HeadingAngle : 385|10@0+ (0.01,-3.14) [-3.14|3.14] "rad"  LAS
 SG_ RRC_OBJ9_Dy : 487|11@0+ (0.125,-128) [-128|127.875] "m"  LAS
 SG_ RRC_OBJ9_Dx : 439|13@0+ (0.0625,-256) [-256|255.9375] "m"  LAS
 SG_ RRC_OBJ9_Vy : 441|10@0+ (0.125,-64) [-64|63.875] "m/s"  LAS
 SG_ RRC_OBJ9_Vx : 463|12@0+ (0.0625,-128) [-128|127.9375] "m/s"  LAS
 SG_ RRC_OBJ9_Ay : 467|10@0+ (0.03125,-16) [-16|15.96875] "m/s2"  LAS
 SG_ RRC_OBJ9_Ax : 416|9@0+ (0.0625,-16) [-16|15.9375] "m/s2"  LAS
 SG_ RRC_OBJ9_Location : 473|2@0+ (1,0) [0|3] ""  LAS
 SG_ RRC_OBJ9_ExistProb : 120|6@0+ (2,0) [0|100] "%"  LAS
 SG_ RRC_OBJ9_Measured : 4|2@0+ (1,0) [0|3] ""  LAS
 SG_ RRC_OBJ9_ObstacleProb : 274|6@0+ (2,0) [0|100] "%"  LAS
 SG_ RRC_CRCCheck_2BF : 503|16@0+ (1,0) [0|65535] ""  LAS
 SG_ RRC_RollingCounter_2BF : 491|4@0+ (1,0) [0|15] ""  LAS

BO_ 644 GW_284: 64 GW
 SG_ RRC_OBJ1_RefPointDy : 7|11@0+ (0.125,-128) [-128|127.875] "m"  LAS
 SG_ RRC_OBJ1_RefPointDx : 12|13@0+ (0.0625,-256) [-256|255.9375] "m"  LAS
 SG_ RRC_OBJ1_RefPointLoc : 31|3@0+ (1,0) [0|7] ""  LAS
 SG_ RRC_OBJ2_RefPointDy : 28|11@0+ (0.125,-128) [-128|127.875] "m"  LAS
 SG_ RRC_OBJ2_RefPointDx : 33|13@0+ (0.0625,-256) [-256|255.9375] "m"  LAS
 SG_ RRC_OBJ2_RefPointLoc : 52|3@0+ (1,0) [0|7] ""  LAS
 SG_ RRC_OBJ3_RefPointDy : 49|11@0+ (0.125,-128) [-128|127.875] "m"  LAS
 SG_ RRC_OBJ3_RefPointDx : 70|13@0+ (0.0625,-256) [-256|255.9375] "m"  LAS
 SG_ RRC_OBJ3_RefPointLoc : 73|3@0+ (1,0) [0|7] ""  LAS
 SG_ RRC_OBJ4_RefPointDy : 86|11@0+ (0.125,-128) [-128|127.875] "m"  LAS
 SG_ RRC_OBJ4_RefPointDx : 91|13@0+ (0.0625,-256) [-256|255.9375] "m"  LAS
 SG_ RRC_OBJ4_RefPointLoc : 110|3@0+ (1,0) [0|7] ""  LAS
 SG_ RRC_OBJ5_RefPointDy : 107|11@0+ (0.125,-128) [-128|127.875] "m"  LAS
 SG_ RRC_OBJ5_RefPointDx : 112|13@0+ (0.0625,-256) [-256|255.9375] "m"  LAS
 SG_ RRC_OBJ5_RefPointLoc : 131|3@0+ (1,0) [0|7] ""  LAS
 SG_ RRC_OBJ6_RefPointDy : 128|11@0+ (0.125,-128) [-128|127.875] "m"  LAS
 SG_ RRC_OBJ6_RefPointDx : 149|13@0+ (0.0625,-256) [-256|255.9375] "m"  LAS
 SG_ RRC_OBJ6_RefPointLoc : 152|3@0+ (1,0) [0|7] ""  LAS
 SG_ RRC_OBJ7_RefPointDy : 165|11@0+ (0.125,-128) [-128|127.875] "m"  LAS
 SG_ RRC_OBJ7_RefPointDx : 170|13@0+ (0.0625,-256) [-256|255.9375] "m"  LAS
 SG_ RRC_OBJ7_RefPointLoc : 189|3@0+ (1,0) [0|7] ""  LAS
 SG_ RRC_OBJ8_RefPointDy : 186|11@0+ (0.125,-128) [-128|127.875] "m"  LAS
 SG_ RRC_OBJ8_RefPointDx : 207|13@0+ (0.0625,-256) [-256|255.9375] "m"  LAS
 SG_ RRC_OBJ8_RefPointLoc : 210|3@0+ (1,0) [0|7] ""  LAS
 SG_ RRC_OBJ9_RefPointDy : 223|11@0+ (0.125,-128) [-128|127.875] "m"  LAS
 SG_ RRC_OBJ9_RefPointDx : 228|13@0+ (0.0625,-256) [-256|255.9375] "m"  LAS
 SG_ RRC_OBJ9_RefPointLoc : 247|3@0+ (1,0) [0|7] ""  LAS
 SG_ RRC_OBJ10_RefPointDy : 244|11@0+ (0.125,-128) [-128|127.875] "m"  LAS
 SG_ RRC_OBJ10_RefPointDx : 249|13@0+ (0.0625,-256) [-256|255.9375] "m"  LAS
 SG_ RRC_OBJ10_RefPointLoc : 268|3@0+ (1,0) [0|7] ""  LAS

BO_ 1468 LAS_5BC: 16 LAS
 SG_ LasHwVers0 : 71|8@0+ (1,0) [0|255] "" Vector__XXX
 SG_ LasHwVers1 : 79|8@0+ (1,0) [0|255] "" Vector__XXX
 SG_ LasHwVers2 : 87|8@0+ (1,0) [0|255] "" Vector__XXX
 SG_ LasHwVers3 : 95|8@0+ (1,0) [0|255] "" Vector__XXX
 SG_ LasHwVers4 : 103|16@0+ (1,0) [0|65535] "" Vector__XXX
 SG_ LasHwVers5 : 119|8@0+ (1,0) [0|255] "" Vector__XXX
 SG_ LasHwVers6 : 127|8@0+ (1,0) [0|255] "" Vector__XXX
 SG_ LasSwVers0 : 7|8@0+ (1,0) [0|255] "" Vector__XXX
 SG_ LasSwVers1 : 15|8@0+ (1,0) [0|255] "" Vector__XXX
 SG_ LasSwVers2 : 23|8@0+ (1,0) [0|255] "" Vector__XXX
 SG_ LasSwVers3 : 31|8@0+ (1,0) [0|255] "" Vector__XXX
 SG_ LasSwVers4 : 39|16@0+ (1,0) [0|65535] "" Vector__XXX
 SG_ LasSwVers5 : 55|8@0+ (1,0) [0|255] "" Vector__XXX
 SG_ LasSwVers6 : 63|8@0+ (1,0) [0|255] "" Vector__XXX

CM_ SG_ 903 BCM_CRCCheck_387 "CRCCheck_SAE_J1850_2001,X8+X4+X3+X2+1";
CM_ SG_ 903 BCM_RainfallLevel "/";
CM_ SG_ 903 BCM_RLS_Light_switch_reason "0000 0000 Day
---- ---1 Twilight
---- --1- Darkness
---- -1-- Precipitation
---- 1--- Tunnel
---1 ---- Underground car park Exit from tunnel/underground car park
--1- ---- High speed
1111 1111 Signal invalid";
CM_ SG_ 903 BCM_RollingCounter_387 "rolling counter";
CM_ SG_ 651 BCM_TurnLightSwitchSts "/";
CM_ SG_ 651 BCM_RollingCounter_28B "rolling counter";
CM_ SG_ 651 BCM_CRCCheck_28B "CRCCheck_SAE_J1850_2001,X8+X4+X3+X2+1";
CM_ SG_ 648 BcmCrcChk288 "CRCCheck_SAE_J1850_2001,X8+X4+X3+X2+1";
CM_ SG_ 648 BcmEmgyLiSts "/";
CM_ SG_ 80 SrsCrashOutpSts ", 020ms10500ms
0x2~0xF:NotUsed";
CM_ SG_ 80 SrsCrashOutpStsChks "Checksum
:(SRS_CrashOutputStatus)XOR0xF";
CM_ SG_ 80 SrsCrcChk050 "CRC_8X8+X4+X3+X2+1";
CM_ SG_ 353 VcuComFltSts "0
";
CM_ SG_ 353 VcuShiftLvlPosn "0x5~0xE:Reserved";
CM_ SG_ 353 VcuCrcChk161 "16-bit CCITT-FALSE CRC161021h
Refer to AUTOSAR <Specification of CRC Routines>";
CM_ SG_ 680 TmsAcEnvtlTVld "/";
CM_ SG_ 943 HU_AccidentProneDistance "(0x0~0x3C)*10:0~600m";
CM_ SG_ 943 HU_BridgeDis "(0x0~0x3C)*10:0~600m";
CM_ SG_ 943 HU_CRCCheck_3AF "8 bit CRC after SAE J1850 according to scheme(c-code), is generated over Byte 0 to Byte 6";
CM_ SG_ 943 HU_CRCCheck_3BB "8 bit CRC after SAE J1850 according to scheme(c-code), is generated over Byte 0 to Byte 6";
CM_ SG_ 943 HU_CurveDistance "(0x0~0x3C)*10:0~600m";
CM_ SG_ 943 HU_EnterCurveInfo "/";
CM_ SG_ 943 HU_EnterRampInfo "/";
CM_ SG_ 943 HU_IntervalVelocityDis "(0x0~0x3C)*10:0~600m";
CM_ SG_ 943 HU_LaneConfluenceDis "(0x0~0x3C)*10:0~600m";
CM_ SG_ 943 HU_LaneType_ID1 "ADAS EHP for _V3.0_20200521 LaneType";
CM_ SG_ 943 HU_LaneType_ID2 "ADAS EHP for _V3.0_20200521 LaneType";
CM_ SG_ 943 HU_LaneType_ID3 "ADAS EHP for _V3.0_20200521 LaneType";
CM_ SG_ 943 HU_LaneType_ID4 "ADAS EHP for _V3.0_20200521 LaneType";
CM_ SG_ 943 HU_LaneType_ID5 "ADAS EHP for _V3.0_20200521 LaneType";
CM_ SG_ 943 HU_LaneType_ID6 "ADAS EHP for _V3.0_20200521 LaneType";
CM_ SG_ 943 HU_NavCurrentRoadType "1.ADAS:
0x0:Road Type Unknown:Small road, Walking Street
0x1:Road Type Class 1:Secondary Roads
0x2:Road Type Class 2:Mainly Road in City
0x3:Road Type Class 3:Mainly Road in City, Normal Province Road, Mainly street
0x4:Road Type Class 4:Province Road, Mainly Road 
0x5:Road Type Class 5:Highway, National Road, Speed road
 
0x6~0x7:Reserved
2.ADAS:
0x0:
0x1:
0x2:
0x3:
0x4:
0x5:
0x6:
0x7:
";
CM_ SG_ 943 HU_NavSpeedLimit "0x1-0x205";
CM_ SG_ 943 HU_NavSpeedLimitStatus "/";
CM_ SG_ 943 HU_NavSpeedLimitType "/";
CM_ SG_ 943 HU_NavSpeedLimitUnits "/";
CM_ SG_ 943 HU_NavStatus "/";
CM_ SG_ 943 HU_RampDistance "(0x0~0x3C)*10:0~600m";
CM_ SG_ 943 HU_RampInfo "/";
CM_ SG_ 943 HU_RollingCounter_3AF "message counter";
CM_ SG_ 943 HU_RollingCounter_3BB "message counter";
CM_ SG_ 943 HU_ServiceRoadDis "(0x0~0x3C)*10:0~600m";
CM_ SG_ 943 HU_SlopeGradient "-51.1+0.1*X
0x3FF:unknown";
CM_ SG_ 943 HU_SlopeGradient_100m "-51.1+0.1*X
0x3FF:unknown";
CM_ SG_ 943 HU_SlopeGradient_10m "-51.1+0.1*X
0x2FF:unknown
";
CM_ SG_ 943 HU_SlopeGradient_20m "-51.1+0.1*X
0x3FF:unknown";
CM_ SG_ 943 HU_SlopeGradient_30m "-51.1+0.1*X
0x3FF:unknown";
CM_ SG_ 943 HU_SlopeGradient_40m "-51.1+0.1*X
0x3FF:unknown";
CM_ SG_ 943 HU_SlopeGradient_50m "-51.1+0.1*X
0x3FF:unknown";
CM_ SG_ 943 HU_SlopeGradientFar "-51.1+0.1*X
0x3FF:unknown";
CM_ SG_ 943 HU_SpeedLimitDistance "(0x0~0x3C)*10:0~600m";
CM_ SG_ 943 HU_WeatherType "ADASIS V2";
CM_ SG_ 1287 HU_AutoBrakeEnable "/";
CM_ SG_ 1287 HU_CruiseControlSet "/";
CM_ SG_ 1287 HU_HMAEnable "513()514()514()";
CM_ SG_ 1287 HU_IACCEnable "513()514()514()";
CM_ SG_ 1287 HU_LASModeSelection "513()514()514()";
CM_ SG_ 1287 HU_LASWarningModeSelection "513()514()514()";
CM_ SG_ 1287 HU_LDWShakeLev "513()514()514()";
CM_ SG_ 1287 HU_OverspeedSoundWarEnable "513()514()514()";
CM_ SG_ 1287 HU_OverspeedWarningEnable "513()514()514()";
CM_ SG_ 1287 HU_OverspeedWarningOffset "513()514()514()";
CM_ SG_ 1287 HU_TSRSwitch "513()514()514()";
CM_ SG_ 1287 HU_VC_CruiseControl "/";
CM_ SG_ 1287 HU_VC_CruiseSetDistance "/";
CM_ SG_ 1287 HU_VC_CruiseSetSpeed "/";
CM_ SG_ 964 HU_Byroad "/";
CM_ SG_ 964 HU_CRCCheck_3B8 "8 bit CRC after SAE J1850 according to scheme(c-code), is generated over Byte 0 to Byte 6";
CM_ SG_ 964 HU_CRCCheck_3C2 "8 bit CRC after SAE J1850 according to scheme(c-code), is generated over Byte 0 to Byte 6";
CM_ SG_ 964 HU_CRCCheck_3C4 "8 bit CRC after SAE J1850 according to scheme(c-code), is generated over Byte 0 to Byte 6";
CM_ SG_ 964 HU_CRCCheck_3C6 "8 bit CRC after SAE J1850 according to scheme(c-code), is generated over Byte 0 to Byte 6";
CM_ SG_ 964 HU_CRCCheck_3C7 "8 bit CRC after SAE J1850 according to scheme(c-code), is generated over Byte 0 to Byte 6";
CM_ SG_ 964 HU_EnterSlopeInfo "/";
CM_ SG_ 964 HU_EnterTunnelInfo "/";
CM_ SG_ 964 HU_FallingRockDi "(0x0~0x3C)*10:0~600m";
CM_ SG_ 964 HU_ForwardRoadType "1.ADAS:
0x0:Road Type Unknown:Small road, Walking Street
0x1:Road Type Class 1:Secondary Roads
0x2:Road Type Class 2:Mainly Road in City
0x3:Road Type Class 3:Mainly Road in City, Normal Province Road, Mainly street
0x4:Road Type Class 4:Province Road, Mainly Road 
0x5:Road Type Class 5:Highway, National Road, Speed road
 
0x6~0x7:Reserved
2.ADAS:
0x0:
0x1:
0x2:
0x3:
0x4:
0x5:
0x6:
0x7:
";
CM_ SG_ 964 HU_NavGuiganceStatus "/";
CM_ SG_ 964 HU_RoadCurvature "0x0~0x1FE:-0.16192 ~ -0.00001
0x1FFF:00
0x200~0x3FE:0.00001 ~ 0.16192
0x3FF:unknown";
CM_ SG_ 964 HU_RoadCurvature_100m "0x0~0x1FE:-0.16192 ~ -0.00001
0x1FFF:00
0x200~0x3FE:0.00001 ~ 0.16192
0x3FF:unknown";
CM_ SG_ 964 HU_RoadCurvature_10m "0x0~0x1FE:-0.16192 ~ -0.00001
0x1FFF:00
0x200~0x3FE:0.00001 ~ 0.16192
0x3FF:unknown";
CM_ SG_ 964 HU_RoadCurvature_20m "0x0~0x1FE:-0.16192 ~ -0.00001
0x1FFF:00
0x200~0x3FE:0.00001 ~ 0.16192
0x3FF:unknown";
CM_ SG_ 964 HU_RoadCurvature_300m "0x0~0x1FE:-0.16192 ~ -0.00001
0x1FFF:00
0x200~0x3FE:0.00001 ~ 0.16192
0x3FF:unknown";
CM_ SG_ 964 HU_RoadCurvature_30m "0x0~0x1FE:-0.16192 ~ -0.00001
0x1FFF:00
0x200~0x3FE:0.00001 ~ 0.16192
0x3FF:unknown";
CM_ SG_ 964 HU_RoadCurvature_400m "0x0~0x1FE:-0.16192 ~ -0.00001
0x1FFF:00
0x200~0x3FE:0.00001 ~ 0.16192
0x3FF:unknown";
CM_ SG_ 964 HU_RoadCurvature_40m "0x0~0x1FE:-0.16192 ~ -0.00001
0x1FFF:00
0x200~0x3FE:0.00001 ~ 0.16192
0x3FF:unknown";
CM_ SG_ 964 HU_RoadCurvature_50m "0x0~0x1FE:-0.16192 ~ -0.00001
0x1FFF:00
0x200~0x3FE:0.00001 ~ 0.16192
0x3FF:unknown";
CM_ SG_ 964 HU_RoadCurvature_600m "0x0~0x1FE:-0.16192 ~ -0.00001
0x1FFF:00
0x200~0x3FE:0.00001 ~ 0.16192
0x3FF:unknown";
CM_ SG_ 964 HU_RoadCurvature_60m "0x0~0x1FE:-0.16192 ~ -0.00001
0x1FFF:00
0x200~0x3FE:0.00001 ~ 0.16192
0x3FF:unknown";
CM_ SG_ 964 HU_RoadCurvature_70m "0x0~0x1FE:-0.16192 ~ -0.00001
0x1FFF:00
0x200~0x3FE:0.00001 ~ 0.16192
0x3FF:unknown";
CM_ SG_ 964 HU_RoadCurvature_80m "0x0~0x1FE:-0.16192 ~ -0.00001
0x1FFF:00
0x200~0x3FE:0.00001 ~ 0.16192
0x3FF:unknown";
CM_ SG_ 964 HU_RoadCurvature_90m "0x0~0x1FE:-0.16192 ~ -0.00001
0x1FFF:00
0x200~0x3FE:0.00001 ~ 0.16192
0x3FF:unknown";
CM_ SG_ 964 HU_RoadCurvatureFar "0x0~0x1FE:-0.16192 ~ -0.00001
0x1FFF:00
0x200~0x3FE:0.00001 ~ 0.16192
0x3FF:unknown";
CM_ SG_ 964 HU_RollingCounter_3B8 "message counter";
CM_ SG_ 964 HU_RollingCounter_3C2 "message counter";
CM_ SG_ 964 HU_RollingCounter_3C4 "message counter";
CM_ SG_ 964 HU_RollingCounter_3C6 "message counter";
CM_ SG_ 964 HU_RollingCounter_3C7 "message counter";
CM_ SG_ 964 HU_SlopeDistance "(0x0~0x3C)*10:0~600m";
CM_ SG_ 964 HU_SlopeGradient_300m "-51.1+0.1*X
0x3FF:unknown";
CM_ SG_ 964 HU_To_Branch_Dis "(0x0~0x3C)*10:0~600m";
CM_ SG_ 964 HU_To_Construction_Dis "(0x0~0x3C)*10:0~600m";
CM_ SG_ 964 HU_To_NumchangeOfLanes_Dist "(0x0~0x3C)*10:0~600m";
CM_ SG_ 964 HU_To_TrafficAccident_Dis "(0x0~0x3C)*10:0~600m";
CM_ SG_ 964 HU_TollDis "(0x0~0x3C)*10:0~600m";
CM_ SG_ 964 HU_TunnelDistance "(0x0~0x3C)*10:0~600m";
CM_ SG_ 964 HU_TunnelLength "(0x0~0x3C)*10:0~600m";
CM_ SG_ 854 IMS_CRCCheck_356 "CRCCheck_SAE_J1850_2001,X8+X4+X3+X2+1";
CM_ SG_ 854 IMS_CRCCheck_360 "CRCCheck_SAE_J1850_2001,X8+X4+X3+X2+1";
CM_ SG_ 854 IMS_DriverEyeClosestatus "/";
CM_ SG_ 854 IMS_DriverEyeConfidence "/";
CM_ SG_ 854 IMS_DriverEyeDetect "/";
CM_ SG_ 854 IMS_DriverEyesFovArea "/";
CM_ SG_ 854 IMS_EyeDetectSatus "10";
CM_ SG_ 854 IMS_RollingCounter_356 "rolling counter";
CM_ SG_ 854 IMS_RollingCounter_360 "rolling counter";
CM_ SG_ 734 IP_CRCCheck_2DE "CRCCheck_SAE_J1850_2001,X8+X4+X3+X2+1";
CM_ SG_ 734 IP_DISFail "GW";
CM_ SG_ 734 IP_QDashACCFail "GW";
CM_ SG_ 734 IP_RollingCounter_2DE "rolling counter";
CM_ SG_ 722 CdcCycChk2D2 "16-bit CCITT-FALSE CRC161021h
Refer to AUTOSAR <Specification of CRC Routines>";
CM_ SG_ 1302 HU_CurrentLocationLongitude "0x0FFFFFFF0";
CM_ SG_ 1302 HU_CurrentLocationLatitude "0x7FFFFFF0";
CM_ SG_ 794 ACC_RollingCounter_36D "rolling counter";
CM_ SG_ 794 ACC_CRCCheck_36D "CRCCheck_SAE_J1850_2001,X8+X4+X3+X2+1";
CM_ SG_ 794 ACC_LASModeSelectionStatus "/";
CM_ SG_ 794 ACC_LASWarningModeSelectionSts "/";
CM_ SG_ 794 ACC_IACCHWAEnable "/";
CM_ SG_ 794 ACC_RollingCounter_31A "rolling counter";
CM_ SG_ 794 ACC_CRCCheck_31A "16-bit CCITT-FALSE CRC161021h
Refer to AUTOSAR <Specification of CRC Routines>";
CM_ SG_ 794 ACC_RollingCounter_30A "rolling counter";
CM_ SG_ 794 ACC_IACCHWAMode "CRCCheck_SAE_J1850_2001,X8+X4+X3+X2+1";
CM_ SG_ 794 ACC_DriverHandsOffStatus "/";
CM_ SG_ 794 ACC_IACCHWATextInfoForDriver "/";
CM_ SG_ 794 ACC_LatTakeoverReq "/";
CM_ SG_ 794 ACC_HostLaneLeftStatus "ACCLASACCAPAAVM";
CM_ SG_ 794 ACC_HostLaneRightStatus "ACCLASACCAPAAVM";
CM_ SG_ 794 ACC_LLaneMarkerType "ACCLASACCAPAAVM";
CM_ SG_ 794 ACC_RLaneMarkerType "ACCLASACCAPAAVM";
CM_ SG_ 580 ACC_ABAActive "/";
CM_ SG_ 580 ACC_ABAlevel "/";
CM_ SG_ 580 ACC_ACCMode "/";
CM_ SG_ 580 ACC_ACCTargetAcceleration "ACC target acceleration for transmission.";
CM_ SG_ 580 ACC_AccTrqReq "/";
CM_ SG_ 580 ACC_AccTrqReqActive "/";
CM_ SG_ 580 ACC_AEBActive "/";
CM_ SG_ 580 ACC_AEBTargetDeceleration "target deceleration value from AEB/EBA/FCTB/RCTB";
CM_ SG_ 580 ACC_AEBVehilceHoldReq "/";
CM_ SG_ 580 ACC_AWBActive "/";
CM_ SG_ 580 ACC_AWBlevel "/";
CM_ SG_ 580 ACC_CDDActive "/";
CM_ SG_ 580 ACC_CRCCheck_24E "CRCCheck_SAE_J1850_2001,X8+X4+X3+X2+1";
CM_ SG_ 580 ACC_CRCCheck_25E "CRCCheck_SAE_J1850_2001,X8+X4+X3+X2+1";
CM_ SG_ 580 ACC_DecToStop "/";
CM_ SG_ 580 ACC_Driveoff_Request "/";
CM_ SG_ 580 ACC_FCWActive "/";
CM_ SG_ 580 ACC_FCWPreWarning "/";
CM_ SG_ 580 ACC_LDWStatus "ACCLASACCAPAAVM";
CM_ SG_ 580 ACC_LDWVibrationWarningReq "ACCLASACCAPAAVM";
CM_ SG_ 580 ACC_LKAStatus "GW";
CM_ SG_ 580 ACC_PrefillActive "/";
CM_ SG_ 580 ACC_RollingCounter_24E "rolling counter";
CM_ SG_ 580 ACC_RollingCounter_25E "rolling counter";
CM_ SG_ 775 ACC_ACCEPBrequest "/";
CM_ SG_ 775 ACC_ACCTargetType "/";
CM_ SG_ 775 ACC_CRCCheck_307 "16-bit CCITT-FALSE CRC161021h
Refer to AUTOSAR <Specification of CRC Routines>";
CM_ SG_ 775 ACC_CRCCheck_322 "CRCCheck_SAE_J1850_2001,X8+X4+X3+X2+1";
CM_ SG_ 775 ACC_CRCCheck_344 "CRCCheck_SAE_J1850_2001,X8+X4+X3+X2+1";
CM_ SG_ 775 ACC_CRCCheck_35E "CRCCheck_SAE_J1850_2001,X8+X4+X3+X2+1";
CM_ SG_ 775 ACC_CRCCheck_35F "CRCCheck_SAE_J1850_2001,X8+X4+X3+X2+1";
CM_ SG_ 775 ACC_DistanceLevel "/";
CM_ SG_ 775 ACC_HostTargetDetection "/";
CM_ SG_ 775 ACC_LngTakeOverReq "/";
CM_ SG_ 775 ACC_ObjValid "/";
CM_ SG_ 775 ACC_SetSpeed "the set speed from driver, should be available
 as long as ACC is active.";
CM_ SG_ 775 ACC_TextInfoForDriver "/";
CM_ SG_ 775 ACC_TimeGapSet "/";
CM_ SG_ 775 ACC_RollingCounter_307 "rolling counter";
CM_ SG_ 775 ACC_RollingCounter_322 "rolling counter";
CM_ SG_ 775 ACC_RollingCounter_344 "rolling counter";
CM_ SG_ 775 ACC_RollingCounter_35E "rolling counter";
CM_ SG_ 775 ACC_RollingCounter_35F "rolling counter";
CM_ SG_ 786 ACC_ACCTargetID "/";
CM_ SG_ 786 ACC_LLaneDistanceFusion "/";
CM_ SG_ 786 ACC_RLaneDistanceFusion "/";
CM_ SG_ 786 ACC_RollingCounter_3E4 "rolling counter";
CM_ SG_ 786 ACC_CRCCheck_3E4 "CRCCheck_SAE_J1850_2001,X8+X4+X3+X2+1";
CM_ SG_ 786 ADS_RollingCounter_312 "rolling counter";
CM_ SG_ 786 ADS_CRCCheck_312 "16-bit CCITT-FALSE CRC161021h
Refer to AUTOSAR <Specification of CRC Routines>";
CM_ SG_ 922 LAS_RollingCounter_37D "rolling counter";
CM_ SG_ 922 LAS_CRCCheck_37D "CRCCheck_SAE_J1850_2001,X8+X4+X3+X2+1";
CM_ SG_ 922 LAS_OverspeedVisualWarning "/";
CM_ SG_ 922 LAS_OverspeedSoundWarning "/";
CM_ SG_ 922 LAS_OverspeedWarningEnableStatus "/";
CM_ SG_ 922 LAS_OverspeedWarningOffset "/";
CM_ SG_ 922 LAS_FrontCameraFailureStatus "LASLASAPAAVM";
CM_ SG_ 922 LAS_FrontCameraCalibrationStatus "LASLASAPAAVM";
CM_ SG_ 922 LAS_TSRStatus "GW";
CM_ SG_ 922 LAS_TSRHostSpdLimit "/";
CM_ SG_ 922 LAS_TSRHostSpdLimitUnits "GW";
CM_ SG_ 922 LAS_HMAStatus "GW";
CM_ SG_ 922 LAS_HMALightDistribution "GW";
CM_ SG_ 922 LAS_HMAEnableStatus "/";
CM_ SG_ 922 LAS_TSREnable "/";
CM_ SG_ 922 LAS_OverspeedSoundWarningEnSt "/";
CM_ SG_ 922 LAS_RollingCounter_332 "rolling counter";
CM_ SG_ 922 LAS_CRCCheck_332 "CRCCheck_SAE_J1850_2001,X8+X4+X3+X2+1";
CM_ SG_ 922 LAS_RollingCounter_3D4 "rolling counter";
CM_ SG_ 922 LAS_CRCCheck_3D4 "CRCCheck_SAE_J1850_2001,X8+X4+X3+X2+1";
CM_ SG_ 922 LAS_TSRLeftLaneSpdLimit "GW
0x0:no speed limit detected

0x1:SL5

0x2:SL10


0x32:SL160

0x33~0x253:Reserved

0x254:Unknown

0x255:SLEND";
CM_ SG_ 922 LAS_TSRRightLaneSpdLimit "GW
0x0:no speed limit detected

0x1:SL5

0x2:SL10


0x32:SL160

0x33~0x253:Reserved

0x254:Unknown

0x255:SLEND";
CM_ SG_ 922 LAS_RollingCounter_3C0 "rolling counter";
CM_ SG_ 922 LAS_CRCCheck_3C0 "CRCCheck_SAE_J1850_2001,X8+X4+X3+X2+1";
CM_ SG_ 922 LAS_TSRLeftLaneStatus "GW";
CM_ SG_ 922 LAS_TSRRightLaneStatus "GW";
CM_ SG_ 922 LAS_RollingCounter_39A "rolling counter";
CM_ SG_ 922 LAS_CRCCheck_39A "16-bit CCITT-FALSE CRC161021h
Refer to AUTOSAR <Specification of CRC Routines>";
CM_ SG_ 898 ACC_CRCCheck_3E6 "CRCCheck_SAE_J1850_2001,X8+X4+X3+X2+1";
CM_ SG_ 898 ACC_RollingCounter_3E6 "rolling counter";
CM_ SG_ 898 ACC_RollingCounter_382 "rolling counter";
CM_ SG_ 898 ACC_CRCCheck_382 "16-bit CCITT-FALSE CRC161021h
Refer to AUTOSAR <Specification of CRC Routines>";
CM_ SG_ 368 EPS_ActualTorsionBarTorq "?
?EPS ECU Initial (0)
?Invalid (0x7FF)
10msCD5698ms";
CM_ SG_ 368 EPS_CRCCheck_170 "10msCD5698msCRCCheck_SAE_J1850_2001,X8+X4+X3+X2+1";
CM_ SG_ 368 EPS_MaxSafetyTorsionBarTorq "?
?EPS ECU Initial (0)
?Invalid (0x7FF)
10msCD5698ms";
CM_ SG_ 368 EPS_MinSafetyTorsionBarTorq "10msCD5698ms
?
?EPS ECU Initial (0)
?Invalid (0x7FF)";
CM_ SG_ 368 EPS_RollingCounter_170 "10msCD5698ms";
CM_ SG_ 591 EPS_CRCCheck_24F "CRCCheck_SAE_J1850_2001,X8+X4+X3+X2+1";
CM_ SG_ 382 EPS_CRCCheck_17E "10msCD5698ms,CRCCheck_SAE_J1850_2001,X8+X4+X3+X2+1";
CM_ SG_ 382 EPS_LatCtrlActive "10msCD5698ms";
CM_ SG_ 382 EPS_LatCtrlAvailabilityStatus "10msCD5698ms";
CM_ SG_ 382 EPS_MeasuredTorsionBarTorque "1.?(Measured Torsion Bar Torque 0x3FF)*0.01
?
?EPS ECU Initial (0)
?Invalid (0x7FF)
2.10msCD5698ms";
CM_ SG_ 382 EPS_MeasuredTorsionBarTorqValid "10msCD5698ms";
CM_ SG_ 382 EPS_RollingCounter_17E "1.rolling counter
2.10msCD5698ms";
CM_ SG_ 384 EpsCrcChk180 "8bitCRCafterSAEJ1850accordingtoscheme(c-code),isgeneratedoverByte0toByte6";
CM_ SG_ 384 EpsCycCntr180 "messagecounter";
CM_ SG_ 384 EpsSasSteerAg "
Steering wheel angle (N:value of the message):
 :N  0.1 , for 0 < N  32767
 :(N-65536)  0.1 , for N  32767
Note:     that Clockwise rotation is - and anti-Clockwise rotation is +";
CM_ SG_ 384 EpsSteerAgRate ",
SteeringAngleSpeed
(N:valueofthemessage):
:N4,for0<N254
:errorsignaled,forN>254";
CM_ SG_ 706 IbBrkPedlStsGb "RMU";
CM_ SG_ 706 IbCrcChk2C2 "16-bit CCITT-FALSE CRC161021h
Refer to AUTOSAR <Specification of CRC Routines>";
CM_ SG_ 962 EspCrcChk3C2 "16-bit CCITT-FALSE CRC161021h
Refer to AUTOSAR <Specification of CRC Routines>";
CM_ SG_ 523 ESP_ABAactive "/";
CM_ SG_ 523 ESP_ABAavailable "/";
CM_ SG_ 523 ESP_AEBAvailable "/";
CM_ SG_ 523 ESP_AEBdecActive "/";
CM_ SG_ 523 ESP_AWBactive "/";
CM_ SG_ 523 ESP_AWBavailable "/";
CM_ SG_ 523 ESP_BrakeForce "/";
CM_ SG_ 523 ESP_BrakeOverHeatBrakeDiscTemp "/";
CM_ SG_ 523 ESP_PrefillActive "/";
CM_ SG_ 523 ESP_PrefillAvailable "/";
CM_ SG_ 523 ESP_QDCACC "/";
CM_ SG_ 523 EspCrcChk20B "16-bit CCITT-FALSE CRC161021h
Refer to AUTOSAR <Specification of CRC Routines>";
CM_ SG_ 450 EspCrcChk1C2 "16-bit CCITT-FALSE CRC161021h
Refer to AUTOSAR <Specification of CRC Routines>";
CM_ SG_ 450 EspVehStandstill "/";
CM_ SG_ 450 EspLatAccel "
";
CM_ SG_ 450 EspLgtAccel "
";
CM_ SG_ 450 WhlSpdReRiPls "All4wheelpulsesignalsaresentbyABSwithoutfiltering.Theriseedgeandfalledgearebothcountedinit,thewheelpulsemustbesequentialintheway0,1,2254,0,1";
CM_ SG_ 450 WhlSpdReLePls "All4wheelpulsesignalsaresentbyABSwithoutfiltering.Theriseedgeandfalledgearebothcountedinit,thewheelpulsemustbesequentialintheway0,1,2254,0,2";
CM_ SG_ 450 WhlSpdFrntRiPls "All4wheelpulsesignalsaresentbyABSwithoutfiltering.Theriseedgeandfalledgearebothcountedinit,thewheelpulsemustbesequentialintheway0,1,2254,0,3";
CM_ SG_ 450 WhlSpdFrntLePls "All4wheelpulsesignalsaresentbyABSwithoutfiltering.Theriseedgeandfalledgearebothcountedinit,thewheelpulsemustbesequentialintheway0,1,2254,0,4";
CM_ SG_ 450 WhlSpdRiFrntDir "/";
CM_ SG_ 450 WhlSpdLeFrntDir "/";
CM_ SG_ 450 WhlSpdRiReDir "/";
CM_ SG_ 450 WhlSpdLeReDir "/";
CM_ SG_ 450 EspYawAgSpd "
";
CM_ SG_ 450 EspYawAgSpdVld "/";
CM_ SG_ 450 WhlSpdRiFrntDataVld "/";
CM_ SG_ 450 WhlSpdLeFrntDataVld "/";
CM_ SG_ 450 WhlSpdRiReDataVld "/";
CM_ SG_ 450 WhlSpdLeReDataVld "/";
CM_ SG_ 450 WhlSpdRiFrntData "/";
CM_ SG_ 450 WhlSpdLeFrntData "/";
CM_ SG_ 450 WhlSpdRiReData "/";
CM_ SG_ 450 WhlSpdLeReData "/";
CM_ SG_ 450 EspAutoHoldActvSts "/";
CM_ SG_ 450 EspMstCylBrkP "/";
CM_ SG_ 450 EspMstCylBrkPVld "indicatedthepressureofbrakemastercylinder,butnotthepressureofbrake";
CM_ SG_ 450 EspVdcActvSts "/";
CM_ SG_ 450 EspTcsActvSts "/";
CM_ SG_ 450 EspAbsActv "/";
CM_ SG_ 450 EspAbsFailr "/";
CM_ SG_ 450 EspVehSpdVld "TCUDCT";
CM_ SG_ 450 EspVehSpd "187";
CM_ SG_ 466 EspCrcChk1D2 "16-bit CCITT-FALSE CRC161021h
Refer to AUTOSAR <Specification of CRC Routines>";
CM_ SG_ 442 ACC_MotorTorqueMaxLimitRequest "?
?EPS ECU Initial (0)
?0x7FF:Reserved";
CM_ SG_ 442 ACC_MotorTorqueMinLimitRequest "?
?EPS ECU Initial (0)
?0x7FF:Reserved";
CM_ SG_ 442 ACC_LatAngReq "
0x384A-3FFF:Reserved";
CM_ SG_ 442 ACC_RollingCounter_1C0 "GW
rolling counter";
CM_ SG_ 442 ACC_CRCCheck_1C0 "CRCCheck_SAE_J1850_2001,X8+X4+X3+X2+1";
CM_ SG_ 978 EspCrcChk3D2 "16-bit CCITT-FALSE CRC161021h
Refer to AUTOSAR <Specification of CRC Routines>";
CM_ SG_ 1684 LAS_DTC1_HighByte "DTC";
CM_ SG_ 1684 LAS_DTC1_LowByte "DTC";
CM_ SG_ 1684 LAS_DTC1_MiddByte "DTC";
CM_ SG_ 1684 LAS_DTC1_Status "DTC";
CM_ SG_ 1684 LAS_DTC2_HighByte "DTC";
CM_ SG_ 1684 LAS_DTC2_LowByte "DTC";
CM_ SG_ 1684 LAS_DTC2_MiddByte "DTC";
CM_ SG_ 1684 LAS_DTC2_Status "DTC";
CM_ SG_ 676 LCDAR_CRCCheck_2AF "CRCCheck_SAE_J1850_2001,X8+X4+X3+X2+1";
CM_ SG_ 676 LCDAR_RCTBTargetDecel "target deceleration value from AEB/EBA/FCTB/RCTB";
CM_ SG_ 676 LCDAR_RollingCounter_2AF "rolling counter";
CM_ SG_ 676 RRC_CRCCheck_2A4 "16-bit CCITT-FALSE CRC161021h
Refer to AUTOSAR <Specification of CRC Routines>";
CM_ SG_ 676 RRC_RollingCounter_2A4 "/";
CM_ SG_ 906 VcuCRCCheck_38A "CRCCheck_SAE_J1850_2001,X8+X4+X3+X2+1";
CM_ SG_ 906 VcuCrsDstSwtSts "/";
CM_ SG_ 906 VcuCrsResuSwtSts "/";
CM_ SG_ 906 VcuCrsSetSwtSts "/";
CM_ SG_ 906 VcuRollingCounter_38A "rolling counter";
CM_ SG_ 888 ACC_LaneQuality "0.015625*(0x0~0x3F)";
CM_ SG_ 888 ACC_LaneEquationC1 "y=C0+C1*x+(1/2)*C2*x^2+(1/6)*C3*x^3C1-1+(0x0 ~ 0xFFE)*2^(-11))";
CM_ SG_ 888 ACC_LaneEquationC2 "y=C0+C1*x+(1/2)*C2*x^2+(1/6)*C3*x^3C2(-2047 + (0x0 ~ 0xFFE))*2^(-16))";
CM_ SG_ 888 ACC_LaneEquationC3 "y=C0+C1*x+(1/2)*C2*x^2+(1/6)*C3*x^3C3(-2047 + (0x0 ~ 0xFFE))*2^(-21))";
CM_ SG_ 701 RRC_CRCCheck_2BD "16-bit CCITT-FALSE CRC161021h
Refer to AUTOSAR <Specification of CRC Routines>";
CM_ SG_ 701 RRC_RollingCounter_2BD "/";
CM_ SG_ 712 RRC_CRCCheck_2C8 "16-bit CCITT-FALSE CRC161021h
Refer to AUTOSAR <Specification of CRC Routines>";
CM_ SG_ 712 RRC_RollingCounter_2C8 "/";
CM_ SG_ 703 RRC_CRCCheck_2BF "16-bit CCITT-FALSE CRC161021h
Refer to AUTOSAR <Specification of CRC Routines>";
CM_ SG_ 703 RRC_RollingCounter_2BF "/";
CM_ SG_ 1468 LasHwVers0 "ASCIIQJD T037-2019 ";
CM_ SG_ 1468 LasHwVers1 "ASCIIQJD T037-2019 ";
CM_ SG_ 1468 LasHwVers2 "ASCIIQJD T037-2019 ";
CM_ SG_ 1468 LasHwVers3 "ASCIIQJD T037-2019 ";
CM_ SG_ 1468 LasHwVers4 "ASCIIQJD T037-2019 ";
CM_ SG_ 1468 LasHwVers5 "ASCIIQJD T037-2019 ";
CM_ SG_ 1468 LasHwVers6 "ASCIIQJD T037-2019 ";
CM_ SG_ 1468 LasSwVers0 "ASCIIQJD T037-2019 ";
CM_ SG_ 1468 LasSwVers1 "ASCIIQJD T037-2019 ";
CM_ SG_ 1468 LasSwVers2 "ASCIIQJD T037-2019 ";
CM_ SG_ 1468 LasSwVers3 "ASCIIQJD T037-2019 ";
CM_ SG_ 1468 LasSwVers4 "ASCIIQJD T037-2019 ";
CM_ SG_ 1468 LasSwVers5 "ASCIIQJD T037-2019 ";
CM_ SG_ 1468 LasSwVers6 "ASCIIQJD T037-2019 ";
BA_DEF_  "BusType" STRING ;
BA_DEF_  "DBName" STRING ;
BA_DEF_ SG_  "GenSigStartValue" FLOAT 0 100000000000;
BA_DEF_ BO_  "VFrameFormat" ENUM  "StandardCAN","ExtendedCAN","reserved","reserved","reserved","reserved","reserved","reserved","reserved","reserved","reserved","reserved","reserved","reserved","StandardCAN_FD","ExtendedCAN_FD";
BA_DEF_ BO_  "CANFD_BRS" ENUM  "0","1";
BA_DEF_ BO_  "NmMessage" ENUM  "no","Yes";
BA_DEF_ BO_  "GenMsgILSupport" ENUM  "no","Yes";
BA_DEF_ BO_  "GenMsgCycleTime" INT 0 50000;
BA_DEF_ BO_  "GenMsgDelayTime" INT 0 1000;
BA_DEF_ BO_  "GenMsgSendType" ENUM  "Cyclic","NotUsed","NotUsed","NotUsed","NotUsed","Cyclic","NotUsed","IfActive","NoMsgSendType","NotUsed","vector_leerstring";
BA_DEF_DEF_  "BusType" "";
BA_DEF_DEF_  "DBName" "";
BA_DEF_DEF_  "GenSigStartValue" 0;
BA_DEF_DEF_  "VFrameFormat" "StandardCAN";
BA_DEF_DEF_  "CANFD_BRS" "1";
BA_DEF_DEF_  "NmMessage" "";
BA_DEF_DEF_  "GenMsgILSupport" "Yes";
BA_DEF_DEF_  "GenMsgCycleTime" 0;
BA_DEF_DEF_  "GenMsgDelayTime" 0;
BA_DEF_DEF_  "GenMsgSendType" "Cyclic";
BA_ "BusType" "CAN";
BA_ "DBName" "LAS";
BA_ "GenMsgCycleTime" BO_ 1107 1000;
BA_ "NmMessage" BO_ 1107 1;
BA_ "GenMsgCycleTime" BO_ 1030 1000;
BA_ "NmMessage" BO_ 1030 1;
BA_ "GenMsgCycleTime" BO_ 1106 1000;
BA_ "NmMessage" BO_ 1106 1;
BA_ "GenMsgCycleTime" BO_ 903 100;
BA_ "VFrameFormat" BO_ 903 14;
BA_ "GenMsgCycleTime" BO_ 651 40;
BA_ "VFrameFormat" BO_ 651 14;
BA_ "GenMsgCycleTime" BO_ 648 40;
BA_ "VFrameFormat" BO_ 648 14;
BA_ "GenMsgCycleTime" BO_ 1006 100;
BA_ "VFrameFormat" BO_ 1006 14;
BA_ "GenMsgCycleTime" BO_ 80 500;
BA_ "VFrameFormat" BO_ 80 14;
BA_ "GenMsgCycleTime" BO_ 759 100;
BA_ "VFrameFormat" BO_ 759 14;
BA_ "GenMsgCycleTime" BO_ 353 10;
BA_ "VFrameFormat" BO_ 353 14;
BA_ "GenMsgCycleTime" BO_ 680 100;
BA_ "VFrameFormat" BO_ 680 14;
BA_ "GenMsgCycleTime" BO_ 943 100;
BA_ "VFrameFormat" BO_ 943 14;
BA_ "VFrameFormat" BO_ 1287 14;
BA_ "GenMsgCycleTime" BO_ 964 100;
BA_ "VFrameFormat" BO_ 964 14;
BA_ "GenMsgCycleTime" BO_ 854 100;
BA_ "VFrameFormat" BO_ 854 14;
BA_ "GenMsgCycleTime" BO_ 734 50;
BA_ "VFrameFormat" BO_ 734 14;
BA_ "GenMsgCycleTime" BO_ 722 100;
BA_ "VFrameFormat" BO_ 722 14;
BA_ "GenMsgCycleTime" BO_ 1302 1000;
BA_ "VFrameFormat" BO_ 1302 14;
BA_ "GenMsgCycleTime" BO_ 794 100;
BA_ "VFrameFormat" BO_ 794 14;
BA_ "GenMsgCycleTime" BO_ 580 20;
BA_ "VFrameFormat" BO_ 580 14;
BA_ "GenMsgCycleTime" BO_ 775 100;
BA_ "VFrameFormat" BO_ 775 14;
BA_ "GenMsgCycleTime" BO_ 786 100;
BA_ "VFrameFormat" BO_ 786 14;
BA_ "GenMsgCycleTime" BO_ 922 100;
BA_ "VFrameFormat" BO_ 922 14;
BA_ "GenMsgCycleTime" BO_ 898 100;
BA_ "VFrameFormat" BO_ 898 14;
BA_ "GenMsgCycleTime" BO_ 368 10;
BA_ "VFrameFormat" BO_ 368 14;
BA_ "GenMsgCycleTime" BO_ 591 20;
BA_ "VFrameFormat" BO_ 591 14;
BA_ "GenMsgCycleTime" BO_ 382 10;
BA_ "VFrameFormat" BO_ 382 14;
BA_ "GenMsgCycleTime" BO_ 384 10;
BA_ "VFrameFormat" BO_ 384 14;
BA_ "GenMsgCycleTime" BO_ 706 10;
BA_ "VFrameFormat" BO_ 706 14;
BA_ "GenMsgCycleTime" BO_ 962 10;
BA_ "VFrameFormat" BO_ 962 14;
BA_ "GenMsgCycleTime" BO_ 523 20;
BA_ "VFrameFormat" BO_ 523 14;
BA_ "GenMsgCycleTime" BO_ 450 10;
BA_ "VFrameFormat" BO_ 450 14;
BA_ "GenMsgCycleTime" BO_ 466 10;
BA_ "VFrameFormat" BO_ 466 14;
BA_ "GenMsgCycleTime" BO_ 442 10;
BA_ "VFrameFormat" BO_ 442 14;
BA_ "GenMsgCycleTime" BO_ 978 10;
BA_ "VFrameFormat" BO_ 978 14;
BA_ "GenMsgCycleTime" BO_ 1684 500;
BA_ "VFrameFormat" BO_ 1684 14;
BA_ "GenMsgCycleTime" BO_ 676 50;
BA_ "VFrameFormat" BO_ 676 14;
BA_ "GenMsgCycleTime" BO_ 906 100;
BA_ "VFrameFormat" BO_ 906 14;
BA_ "GenMsgCycleTime" BO_ 957 100;
BA_ "VFrameFormat" BO_ 957 14;
BA_ "GenMsgCycleTime" BO_ 888 100;
BA_ "VFrameFormat" BO_ 888 14;
BA_ "GenMsgCycleTime" BO_ 685 50;
BA_ "VFrameFormat" BO_ 685 14;
BA_ "GenMsgCycleTime" BO_ 701 50;
BA_ "VFrameFormat" BO_ 701 14;
BA_ "GenMsgCycleTime" BO_ 712 50;
BA_ "VFrameFormat" BO_ 712 14;
BA_ "GenMsgCycleTime" BO_ 703 50;
BA_ "VFrameFormat" BO_ 703 14;
BA_ "GenMsgCycleTime" BO_ 644 50;
BA_ "VFrameFormat" BO_ 644 14;
BA_ "GenMsgCycleTime" BO_ 1468 1000;
BA_ "VFrameFormat" BO_ 1468 14;
BA_ "GenSigStartValue" SG_ 903 BCM_RainfallLevel 14;
BA_ "GenSigStartValue" SG_ 903 BCM_RLS_Light_switch_reason 255;
BA_ "GenSigStartValue" SG_ 680 TmsAcEnvtlT 255;
BA_ "GenSigStartValue" SG_ 943 HU_AccidentProneDistance 63;
BA_ "GenSigStartValue" SG_ 943 HU_BridgeDis 63;
BA_ "GenSigStartValue" SG_ 943 HU_CurveDistance 63;
BA_ "GenSigStartValue" SG_ 943 HU_IntervalVelocityDis 63;
BA_ "GenSigStartValue" SG_ 943 HU_LaneConfluenceDis 63;
BA_ "GenSigStartValue" SG_ 943 HU_NavSpeedLimit 254;
BA_ "GenSigStartValue" SG_ 943 HU_RampDistance 1023;
BA_ "GenSigStartValue" SG_ 943 HU_ServiceRoadDis 63;
BA_ "GenSigStartValue" SG_ 943 HU_SlopeGradient 1023;
BA_ "GenSigStartValue" SG_ 943 HU_SlopeGradient_100m 1023;
BA_ "GenSigStartValue" SG_ 943 HU_SlopeGradient_10m 1023;
BA_ "GenSigStartValue" SG_ 943 HU_SlopeGradient_20m 1023;
BA_ "GenSigStartValue" SG_ 943 HU_SlopeGradient_30m 1023;
BA_ "GenSigStartValue" SG_ 943 HU_SlopeGradient_40m 1023;
BA_ "GenSigStartValue" SG_ 943 HU_SlopeGradient_50m 1023;
BA_ "GenSigStartValue" SG_ 943 HU_SlopeGradientFar 1023;
BA_ "GenSigStartValue" SG_ 943 HU_SpeedLimitDistance 63;
BA_ "GenSigStartValue" SG_ 943 HU_WeatherType 63;
BA_ "GenSigStartValue" SG_ 964 HU_Construction_Info 3;
BA_ "GenSigStartValue" SG_ 964 HU_FallingRockDi 63;
BA_ "GenSigStartValue" SG_ 964 HU_FallingRockInfo 3;
BA_ "GenSigStartValue" SG_ 964 HU_Lane_Changtype 3;
BA_ "GenSigStartValue" SG_ 964 HU_RoadCurvature 511;
BA_ "GenSigStartValue" SG_ 964 HU_RoadCurvature_100m 511;
BA_ "GenSigStartValue" SG_ 964 HU_RoadCurvature_10m 511;
BA_ "GenSigStartValue" SG_ 964 HU_RoadCurvature_20m 511;
BA_ "GenSigStartValue" SG_ 964 HU_RoadCurvature_300m 511;
BA_ "GenSigStartValue" SG_ 964 HU_RoadCurvature_30m 511;
BA_ "GenSigStartValue" SG_ 964 HU_RoadCurvature_400m 511;
BA_ "GenSigStartValue" SG_ 964 HU_RoadCurvature_40m 511;
BA_ "GenSigStartValue" SG_ 964 HU_RoadCurvature_50m 511;
BA_ "GenSigStartValue" SG_ 964 HU_RoadCurvature_600m 511;
BA_ "GenSigStartValue" SG_ 964 HU_RoadCurvature_60m 511;
BA_ "GenSigStartValue" SG_ 964 HU_RoadCurvature_70m 511;
BA_ "GenSigStartValue" SG_ 964 HU_RoadCurvature_80m 511;
BA_ "GenSigStartValue" SG_ 964 HU_RoadCurvature_90m 511;
BA_ "GenSigStartValue" SG_ 964 HU_RoadCurvatureFar 511;
BA_ "GenSigStartValue" SG_ 964 HU_SlopeDistance 63;
BA_ "GenSigStartValue" SG_ 964 HU_SlopeGradient_300m 1023;
BA_ "GenSigStartValue" SG_ 964 HU_To_Branch_Dis 63;
BA_ "GenSigStartValue" SG_ 964 HU_To_Construction_Dis 63;
BA_ "GenSigStartValue" SG_ 964 HU_To_NumchangeOfLanes_Dist 63;
BA_ "GenSigStartValue" SG_ 964 HU_To_TrafficAccident_Dis 63;
BA_ "GenSigStartValue" SG_ 964 HU_TollDis 63;
BA_ "GenSigStartValue" SG_ 964 HU_TollInfo 3;
BA_ "GenSigStartValue" SG_ 964 HU_TrafficAccident_Info 3;
BA_ "GenSigStartValue" SG_ 964 HU_TunnelDistance 63;
BA_ "GenSigStartValue" SG_ 964 HU_TunnelLength 63;
BA_ "GenSigStartValue" SG_ 854 IMS_DriverEyeClosestatus 7;
BA_ "GenSigStartValue" SG_ 854 IMS_EyeDetectSatus 255;
BA_ "GenSigStartValue" SG_ 854 IMS_EyeGazeStatus 255;
BA_ "GenSigStartValue" SG_ 854 IMS_HeadDetectSts_Pitch 255;
BA_ "GenSigStartValue" SG_ 854 IMS_HeadDetectSts_Roll 255;
BA_ "GenSigStartValue" SG_ 854 IMS_HeadDetectSts_Yaw 255;
BA_ "GenSigStartValue" SG_ 854 IMS_IMSStatus 1;
BA_ "GenSigStartValue" SG_ 794 ACC_LASModeSelectionStatus 1;
BA_ "GenSigStartValue" SG_ 794 ACC_LASWarningModeSelectionSts 2;
BA_ "GenSigStartValue" SG_ 794 ACC_LLaneMarkerType 7;
BA_ "GenSigStartValue" SG_ 794 ACC_RLaneMarkerType 7;
BA_ "GenSigStartValue" SG_ 580 ACC_ABAlevel 3;
BA_ "GenSigStartValue" SG_ 580 ACC_ACCTargetAcceleration 100;
BA_ "GenSigStartValue" SG_ 580 ACC_AEBTargetDeceleration 32000;
BA_ "GenSigStartValue" SG_ 775 ACC_ACCTargetLngRange 511;
BA_ "GenSigStartValue" SG_ 786 ACC_ACCTargetID 15;
BA_ "GenSigStartValue" SG_ 786 ACC_LLaneDistanceFusion 36;
BA_ "GenSigStartValue" SG_ 786 ACC_RLaneDistanceFusion 36;
BA_ "GenSigStartValue" SG_ 922 LAS_OverspeedWarningOffset 10;
BA_ "GenSigStartValue" SG_ 922 LAS_TLADistance_HostLane 255;
BA_ "GenSigStartValue" SG_ 922 LAS_TLAStopLine_HostLane 255;
BA_ "GenSigStartValue" SG_ 368 EPS_ActualTorsionBarTorq 1024;
BA_ "GenSigStartValue" SG_ 368 EPS_MaxSafetyTorsionBarTorq 1024;
BA_ "GenSigStartValue" SG_ 368 EPS_MinSafetyTorsionBarTorq 1024;
BA_ "GenSigStartValue" SG_ 591 EPS_SteeringTorque 127;
BA_ "GenSigStartValue" SG_ 591 EpsSteerModFb 3;
BA_ "GenSigStartValue" SG_ 382 EPS_MeasuredTorsionBarTorque 1023;
BA_ "GenSigStartValue" SG_ 450 EspLatAccel 3200;
BA_ "GenSigStartValue" SG_ 450 EspLgtAccel 3200;
BA_ "GenSigStartValue" SG_ 450 EspYawAgSpd 8191;
BA_ "GenSigStartValue" SG_ 450 MbRgnTarWhl 32768;
BA_ "GenSigStartValue" SG_ 442 ACC_MotorTorqueMaxLimitRequest 1024;
BA_ "GenSigStartValue" SG_ 442 ACC_MotorTorqueMinLimitRequest 1024;
BA_ "GenSigStartValue" SG_ 442 ACC_LatAngReq 7200;
BA_ "GenSigStartValue" SG_ 442 ADS_Reqmode 4;
BA_ "GenSigStartValue" SG_ 676 LCDAR_RCTBEnable 1;
BA_ "GenSigStartValue" SG_ 676 LCDAR_RCTBTargetDecel 32000;
BA_ "GenSigStartValue" SG_ 676 LCDAR_SystemStatus 1;
BA_ "GenSigStartValue" SG_ 957 HU_CSLAEnable 3;
BA_ "GenSigStartValue" SG_ 888 ACC_LaneEquationC1 2047;
BA_ "GenSigStartValue" SG_ 888 ACC_LaneEquationC2 2047;
BA_ "GenSigStartValue" SG_ 888 ACC_LaneEquationC3 2047;
BA_ "GenSigStartValue" SG_ 685 LCDAL_SystemStatus 1;
VAL_ 903 BCM_RainfallLevel 0 "No rain" 1 "Level 1" 2 "Level 2" 3 "Level 3" 4 "Level 4" 5 "Level 5?" 6 "Level 6" 7 "Level 7" 8 "Level 8" 9 "Level 9" 10 "Level 10" 11 "Level 11" 12 "Level 12" 13 "level 13" 14 "init value" 15 "Invalid value" ;
VAL_ 651 BCM_TurnLightSwitchSts 0 "Not Actived" 1 "Left Actived" 2 "Right Actived" 3 "Invalid" ;
VAL_ 648 BcmAutHeadLiSts 0 "NotActived" 1 "Actived" ;
VAL_ 648 BcmDrvrDoorSts 0 "Close" 1 "Open" ;
VAL_ 648 BcmFrntFogLmpSts 0 "OFF" 1 "ON" 2 "Notused" 3 "Reserved" ;
VAL_ 648 BcmFrntWiperSts 0 "Off" 1 "Low" 2 "High" 3 "Error" ;
VAL_ 648 BcmHiBeamSts 0 "OFF" 1 "ON" 2 "Notused" 3 "Reserved" ;
VAL_ 648 BcmHoodSts 0 "Close" 1 "Open" ;
VAL_ 648 BcmLeReDoorSts 0 "Close" 1 "Open" ;
VAL_ 648 BcmLiSnsrFlt 0 "NOerror" 1 "Error" ;
VAL_ 648 BcmLoBeamSts 0 "OFF" 1 "ON" 2 "Notused" 3 "Reserved" ;
VAL_ 648 BcmPassDoorSts 0 "Close" 1 "Open" ;
VAL_ 648 BcmReFoglmpSts 0 "OFF" 1 "ON" 2 "Notused" 3 "Error" ;
VAL_ 648 BcmRiReDoorSts 0 "Close" 1 "Open" ;
VAL_ 648 BcmStsRainSnsr 0 "NOerror" 1 "Error" ;
VAL_ 648 BcmTurnIndcrLe 0 "OFF" 1 "ON" 2 "Notused" 3 "Error" ;
VAL_ 648 BcmTurnIndcrRi 0 "OFF" 1 "ON" 2 "Notused" 3 "Error" ;
VAL_ 648 BcmEmgyLiSts 0 "OFF" 1 "ON" 2 "Notused" 3 "Error" ;
VAL_ 1006 GW_SafCertSts 0 "Inactive" 1 "Success" 2 "failed" 3 "" ;
VAL_ 80 SrsCrashOutpSts 0 "NoCrash" 1 "crash" ;
VAL_ 80 SrsDrvrBucSwtSts 0 "Buckled" 1 "Unbuckle" 2 "NotUsed" 3 "NotUsed" ;
VAL_ 80 SrsPassBucSwtSts 0 "Buckled" 1 "Unbuckle" 2 "NotUsed" 3 "NotUsed" ;
VAL_ 80 SrsWarnLampSts 0 "Lampoff" 1 "Lampon" 2 "LampFlashing" 3 "NotUsed" ;
VAL_ 759 TboxLocalTiVld 0 "Valid" 1 "Invalid " ;
VAL_ 353 VcuSimnEpbSwtSts 0 "no request" 1 "apply" ;
VAL_ 353 VcuSimnEpbSwtStsVld 0 "Valid" 1 "Invalid " ;
VAL_ 353 VCUAccPedShield 0 "Unshield" 1 "Shield" ;
VAL_ 353 VCUShiftPostionValid 0 "Valid" 1 "Invalid" ;
VAL_ 353 VcuAccrMod 0 "invalid" 1 "Normal" 2 "Fast" 3 "Slow" ;
VAL_ 353 VcuAccrPedlPosnVld 0 "Valid" 1 "Invalid " ;
VAL_ 353 VcuCalcnAccrPedlPosnVld 0 "Valid" 1 "Invalid " ;
VAL_ 353 VcuComFltSts 0 "no error" 1 "reversible error" 2 "irreversible error" 3 "not defined" ;
VAL_ 353 VcuEnyRecyclMod 0 "Not set" 1 "normal" 2 "strong" ;
VAL_ 353 VcuGearPosn 0 "Invalid" 1 "P" 2 "R" 3 "N" 4 "D" 5 "Reserved" 6 "Reserved  " 7 "Reserved " ;
VAL_ 353 VcuOvrdModReq 0 "Not override" 1 "Override" ;
VAL_ 353 VcuPtTqLimMaxVld 0 "Valid" 1 "Invalid " ;
VAL_ 353 VcuPtTqLimMinVld 0 "Valid" 1 "Invalid " ;
VAL_ 353 VcuPtTqRealVld 0 "Valid" 1 "Invalid " ;
VAL_ 353 VcuPtTqReqAvl 0 "not available" 1 "available" 2 "available degraded" ;
VAL_ 353 VcuRdySts 0 "no Ready" 1 "Ready" ;
VAL_ 353 VcuShiftLvlPosn 0 "Center" 1 "Up" 2 "Down" 3 "Up,Up" 4 "Down,Down" 15 "Invalid" ;
VAL_ 353 VcuVehGearPosnVld 0 "Valid" 1 "Invalid " ;
VAL_ 353 VcuVehWhlReqTqVld 0 "Valid" 1 "Invalid " ;
VAL_ 680 TmsAcEnvtlTVld 0 "Valid" 1 "Invalid" ;
VAL_ 680 TmsFrntBlowMod 0 "blow face" 1 "blow face/blow feet" 2 "blow feet" 3 "blow fee/defroster" 4 "defroster" 7 "error" ;
VAL_ 943 HU_AccidentProne 0 "unknown" 1 "" 2 "reserve" 3 "invalid" ;
VAL_ 943 HU_AccidentProneDistance 61 "Out of Range" 62 "reserved" 63 "unknown" ;
VAL_ 943 HU_BridgeDis 61 "Out of Range" 62 "reserved" 63 "unknown" ;
VAL_ 943 HU_BridgeInfo 0 "unknown" 1 "" 2 "" 3 "invalid" ;
VAL_ 943 HU_CurveDistance 61 "Out of Range" 62 "reserved" 63 "unknown" ;
VAL_ 943 HU_EnterCurveInfo 0 "unknown" 1 "" 2 "" 3 "" ;
VAL_ 943 HU_EnterRampInfo 0 "Unknown" 1 "" 2 "" 3 "" ;
VAL_ 943 HU_IntervalVelocityDis 61 "Out of Range" 62 "reserved" 63 "unknown" ;
VAL_ 943 HU_IntervalVelocityInfo 0 "unknown" 1 "" 2 "" 3 "reserved" ;
VAL_ 943 HU_LaneConfluence 0 "unknown" 1 "" 2 "" 3 "invalid" ;
VAL_ 943 HU_LaneConfluenceDis 61 "Out of Range" 62 "reserved" 63 "unknown" ;
VAL_ 943 HU_NavSpeedLimit 0 "Unlimited" 1 "SL 5" 2 "SL 10" 32 "SL 160" 254 "Unknown" 255 "Invalid" ;
VAL_ 943 HU_NavSpeedLimitStatus 3 "reserved" 2 "reserved" 1 "invalid" 0 "valid" ;
VAL_ 943 HU_NavSpeedLimitType 0 "Unknown" 1 "Speed-Limit Sign" 2 "Road Camera" 3 "Interval Velocity" ;
VAL_ 943 HU_NavSpeedLimitUnits 3 "reserved" 2 "unit mph" 1 "unit kph" 0 "unknown." ;
VAL_ 943 HU_NavStatus 0 "Normal" 1 "Error" ;
VAL_ 943 HU_RampDistance 61 "Out of Range" 62 "reserved" 63 "unknown" ;
VAL_ 943 HU_RampInfo 0 "Unknown" 1 "" 2 "" 3 "" ;
VAL_ 943 HU_ServiceRoad 0 "unknown" 1 "" 2 "reserve" 3 "invalid" ;
VAL_ 943 HU_ServiceRoadDis 61 "Out of Range" 62 "reserved" 63 "unknown" ;
VAL_ 943 HU_SpeedLimitDistance 61 "Out of Range" 62 "reserved" 63 "unknown" ;
VAL_ 1287 HU_AutoBrakeEnable 0 "off" 1 "on" ;
VAL_ 1287 HU_CruiseControlSet 0 "Inactive" 1 "ACC" 2 "CC" 3 "IACC" 4 "HWA" ;
VAL_ 1287 HU_FCWSetting 0 "Early" 1 "Normal" 2 "Late" 3 "Off" ;
VAL_ 1287 HU_HMAEnable 0 "off" 1 "on" ;
VAL_ 1287 HU_IACCEnable 0 "Inactive" 1 "Off" 2 "On" 3 "Reserved" ;
VAL_ 1287 HU_LASModeSelection 0 "Inactive" 1 "LDW" 2 "LKA" 3 "LCS" ;
VAL_ 1287 HU_LASWarningModeSelection 0 "inactive" 1 "visual" 2 "sound" 3 "vibration" 4 "sound and vibration" ;
VAL_ 1287 HU_LDWShakeLev 0 "inactive" 1 "low" 2 "normal" 3 "high" ;
VAL_ 1287 HU_OverspeedSoundWarEnable 0 "Inactive" 1 "Off" 2 "On" 3 "Reserved" ;
VAL_ 1287 HU_OverspeedWarningEnable 0 "Inactive" 1 "OFF" 2 "ON" 3 "Reserved" ;
VAL_ 1287 HU_TSRSwitch 0 "off" 1 "on" ;
VAL_ 1287 HU_VC_CruiseControl 0 "No Request" 1 "ACC Activate" 2 "ACC Resume" 3 "IACC Activate" 4 "IACC Resume" 5 "Cancel" 6 "Reserved" 7 "Invalid" ;
VAL_ 1287 HU_VC_CruiseSetDistance 0 "No Request" 1 "Level 1" 2 "Level 2" 3 "Level 3" 4 "Level 4" 5 "Forward Req" 6 "Backward Req" 7 "Invalid" ;
VAL_ 1287 HU_VC_CruiseSetSpeed 0 "No Request" ;
VAL_ 964 HU_BranchInfo 0 "unknown" 1 "" 2 "" 3 "" ;
VAL_ 964 HU_Byroad 0 "unknown" 1 "" 2 "" 3 "reserved" ;
VAL_ 964 HU_Construction_Info 0 "" 1 "" 2 "" 3 "invalid" ;
VAL_ 964 HU_EnterSlopeInfo 0 "unknown" 1 "" 2 "" 3 "" ;
VAL_ 964 HU_EnterTunnelInfo 0 "unknown" 1 "" 2 "" 3 "" ;
VAL_ 964 HU_FallingRockDi 61 "Out of Range" 62 "reserved" 63 "unknown" ;
VAL_ 964 HU_FallingRockInfo 0 "" 1 "" 2 "" 3 "invalid" ;
VAL_ 964 HU_Lane_Changtype 0 "NO change0x1:Merge" 2 "Separate" 3 "invalid" ;
VAL_ 964 HU_LaneCnt 0 "unknown" ;
VAL_ 964 HU_MapDataUpdateStatus 0 "" 1 "1" 2 "3" 3 "6" 4 "1" ;
VAL_ 964 HU_MapMatchStatus 0 "Successl" 1 "Fail" 2 "" 3 "" ;
VAL_ 964 HU_NavGuiganceStatus 0 "" 1 "" 2 "Reserved" 3 "Reserved" ;
VAL_ 964 HU_RampSide 0 "Unknown" 1 "" 2 "" 3 "" ;
VAL_ 964 HU_Road_TrafficFlow 0 "unknown" 1 "" 2 "" 3 "" 4 "" 5 "" 6 "reserved" 7 "invalid" ;
VAL_ 964 HU_SlopeDistance 61 "Out of Range" 62 "reserved" 63 "unknown" ;
VAL_ 964 HU_To_Branch_Dis 61 "Out of Range" 62 "reserved" 63 "unknown" ;
VAL_ 964 HU_To_Construction_Dis 61 "Out of Range" 62 "reserved" 63 "unknown" ;
VAL_ 964 HU_To_NumchangeOfLanes_Dist 61 "Out of Range" 62 "reserved" 63 "unknown" ;
VAL_ 964 HU_To_TrafficAccident_Dis 61 "Out of Range" 62 "reserved" 63 "unknown" ;
VAL_ 964 HU_TollDis 61 "Out of Range" 62 "reserved" 63 "unknown" ;
VAL_ 964 HU_TollInfo 0 "" 1 "" 2 "" 3 "invalid" ;
VAL_ 964 HU_TrafficAccident_Info 0 "" 1 "" 2 "" 3 "invalid" ;
VAL_ 964 HU_TunnelDistance 61 "Out of Range" 62 "reserved" 63 "unknown" ;
VAL_ 964 HU_TunnelLength 61 "Out of Range" 62 "reserved" 63 "unknown" ;
VAL_ 854 IMS_BrowOffsetValue 0 "0cm" ;
VAL_ 854 IMS_DistractionStatus 0 "Not Distracted" 1 "Distracted" 2 "Unknown" 3 "Invalid" ;
VAL_ 854 IMS_DriverEyeClosestatus 0 "both eyes close" 1 "left eye close" 2 "right ?eye close" 3 "both eyes open" ;
VAL_ 854 IMS_DriverEyeDetect 0 "Invalid" 1 "Not detected" 2 "detected" 3 "Reserved" ;
VAL_ 854 IMS_DriverEyesFovArea 0 "driver forward" 1 "left outside mirror" 2 "right outside mirror" 3 "inside mirror" 4 "front passenger forward" 5 "HU area " 6 "IP area" 7 "gear area" 8 "below IP" 9 "driver door" 10 "front passenger" 11 "driver door window" 12 "up forward" 13 "front passenger door window" 14 "other" 15 "invalid" ;
VAL_ 854 IMS_DriverHeadDetect 0 "Invalid" 1 "Not detected" 2 "detected" 3 "Reserved" ;
VAL_ 854 IMS_DrowsinessStatus 0 "Awake" 1 "Slightly Drowsy" 2 "Drowsy" 3 "Microsleep" 4 "Reserved" 5 "Unavailable" 6 "Unknown" 7 "Invalid" ;
VAL_ 854 IMS_IMSStatus 0 "Off" 1 "Standby" 2 "Active" 3 "Camera Blocked" 4 "Failure" ;
VAL_ 854 IMS_JawOffsetValue 0 "0cm" ;
VAL_ 854 IMS_PhoneCallSts 0 "Not In Phone Call" 1 "In Phone Call" ;
VAL_ 734 IP_DISFail 0 "no error" 1 "error" ;
VAL_ 734 IP_QDashACCFail 0 "no error" 1 "error" 2 "reserved" 3 "reserved" ;
VAL_ 1302 HU_CurrentLocationValid 0 "Valid" 1 "Not Valid" ;
VAL_ 794 ACC_Voiceinfo 0 "no voice" 1 "latentWarning voive" 2 "FCW/AEB voice" 3 "ACC object detect voice" 4 "ACC object disappeared voice" 5 "ACC/IACC takeover request voice" 6 "Lane Left dangerous warning  voice" 7 "Lane Right dangerous warning  voice" 8 "reserved" 9 "IACC Active voice" 10 "IACC exit voice" 11 "reserved" 12 "reserved" 13 "cruise unintended exit" 14 "TrafficWarning" ;
VAL_ 794 ACC_LASModeSelectionStatus 0 "Reserved" 1 "LDW" 2 "LKA" 3 "LCS" ;
VAL_ 794 ACC_LASWarningModeSelectionSts 0 "Reserved" 1 "sound" 2 "vibration" 3 "sound and vibration" ;
VAL_ 794 ACC_IACCHWAEnable 0 "OFF" 1 "ON" ;
VAL_ 794 ACC_IACCHWAMode 0 "off" 1 "standby" 2 "passive" 3 "active" 4 "suspend" 5 "prohibition" 6 "reserved" 7 "failure" ;
VAL_ 794 ACC_DriverHandsOffStatus 0 "hands off" 1 "hands on Level1" 2 "hand on Level2" 3 "unkown" ;
VAL_ 794 ACC_IACCHWATextInfoForDriver 0 "no display" 1 "IACC Cancel" 2 "IACC deactivate" 3 "IACC unintended exit" 4 "unable to activate IACC" 5 "lane condition not available" 6 "ADR/DVR Status not Match" 7 "longitudinal control not available" 8 "IACC not available by EPS" 9 "exceed speed limit" 10 "driver overrides steering" 11 "caution about driving safty" 12 "system error" 13 "prohibition request" 14 "turn light switch on" 15 "Hands on plz" 16 "Please turn on IACC in incall " 17 "unable to active in curve" 18 "unable to active for not in lane/crossing lane" 19 "Longitude Exit" 20 "takeover request with safety stoping" 21 "takeover request with safety stop completed" 22 "other system error" 23 "unable to active in Bad weather" ;
VAL_ 794 ACC_LatTakeoverReq 0 "no request" 1 "level 1 request" 2 "level 2 request" 3 "reserved" ;
VAL_ 794 ACC_HostLaneLeftStatus 0 "No display" 1 "Tracking" 2 "Intervention" 3 "Warning" 4 "Centering" 5 "Crossing" 6 "UDLC Request Active" 7 "reserved" 8 "UDLC Not Active By Obj" ;
VAL_ 794 ACC_HostLaneRightStatus 0 "No display" 1 "Tracking" 2 "Intervention" 3 "Warning" 4 "Centering" 5 "Crossing" 6 "UDLC Request Active" 7 "reserved" 8 "UDLC Not Active By Obj" ;
VAL_ 794 ACC_LLaneMarkerType 0 "Dashed" 1 "solid" 2 "road edge" 3 "double lane mark" 4 "Botts' dots" 5 "other" 6 "fence" 7 "no display" ;
VAL_ 794 ACC_RLaneMarkerType 0 "Dashed" 1 "solid" 2 "road edge" 3 "double lane mark" 4 "Botts' dots" 5 "other" 6 "fence" 7 "no display" ;
VAL_ 580 ACC_ABAActive 0 "not Active" 1 "Active" ;
VAL_ 580 ACC_ABAlevel 0 "level 0" 1 "level 1" 2 "level 2" 3 "level 3" ;
VAL_ 580 ACC_ACCMode 0 "OFF mode" 1 "Passive mode" 2 "StandBy mode" 3 "Active Control mode" 4 "Brake Only mode" 5 "Override" 6 "Stand Wait mode" 7 "Failure mode" ;
VAL_ 580 ACC_AccTrqReqActive 0 "not Active" 1 "Active." ;
VAL_ 580 ACC_AEBActive 0 "not Active" 1 "Active." ;
VAL_ 580 ACC_AEBCtrlType 0 "no request" 1 "AEB C&UAEB" 2 "AEB VRUAEB" 3 "AEB CyclistAEB" 4 "EBA" 5 "FCTBAEB" 6 "RCTB(AEB)" ;
VAL_ 580 ACC_AEBVehilceHoldReq 0 "No hold" 1 "hold" ;
VAL_ 580 ACC_AWBActive 0 "not Active" 1 "Active" ;
VAL_ 580 ACC_AWBlevel 0 "no level" 1 "level 1" 2 "level 2" 3 "level 3" 4 "level 4" ;
VAL_ 580 ACC_CDDActive 0 "not active" 1 "Active" ;
VAL_ 580 ACC_DecToStop 0 "no demand" 1 "demand" ;
VAL_ 580 ACC_Driveoff_Request 0 "No request" 1 "request" ;
VAL_ 580 ACC_EmergencyDataRrdReq 0 "no request" 1 "Event 1 Request" 2 "Event 2 Request" 3 "Image Record" ;
VAL_ 580 ACC_FCWActive 0 "not Active" 1 "Active" ;
VAL_ 580 ACC_FCWPreWarning 0 "no warning" 1 "warning" ;
VAL_ 580 ACC_LDWStatus 0 "Off" 1 "Standby" 2 "Active" 3 "Failure" ;
VAL_ 580 ACC_LDWVibrationWarningReq 0 "No Warning" 1 "Left Warning" 2 "Right Warning" 3 "reserved" ;
VAL_ 580 ACC_LKAStatus 0 "Off" 1 "Standby" 2 "Active" 3 "Failure" ;
VAL_ 580 ACC_PrefillActive 0 "not Active" 1 "Active" ;
VAL_ 580 ACC_FCWLatentWarning 0 "no warning" 1 "warning" ;
VAL_ 775 ACC_ACCEPBrequest 0 "no request" 1 "request" ;
VAL_ 775 ACC_ACCTargetType 0 "no display" 1 "sedan" 2 "motorcycle" 3 "pedestrian" 4 "Bicycle" 5 "Bus" 7 "truck" ;
VAL_ 775 ACC_DistanceLevel 0 "no display" 1 "Level 1" 2 "Level 2" 3 "Level 3" ;
VAL_ 775 ACC_HostTargetDetection 0 "not dectected" 1 "IP display" 2 "Front target" 3 "IACC target" 4 "AEB target" 5 "dangerous targetELKUDLCRCW, etc" ;
VAL_ 775 ACC_LngTakeOverReq 0 "no request" 1 "level 1 request" 2 "level 2 request" 3 "reserved" ;
VAL_ 775 ACC_ObjValid 0 "no object" 1 "target object detected" ;
VAL_ 775 ACC_TextInfoForDriver 0 "no display" 1 "unable to activate ACC" 2 "ACC active control is cancelled" 3 "ACC error by Front Radar" 4 "ACC temporary unavailable by others" 5 "EPB activate" 6 "No forward gear" 7 "Seatbelt unbuckled" 8 "Engine No Running" 9 "ESP off" 10 "bonnet is Open" 11 "Speed over 150kph" 12 "ACC Error by EMS/VCU/TCU" 13 "reserved" 14 "ACC Error by EPBI" 15 "ACC unintended exit warning" 16 "door is open" 17 "brake pedal is applied" 18 "speed reduce by ramp" 19 "speed reduce by tunnel" 20 "ACC error by Front Camera" 21 "speed reduce by condition" 22 "speed reduce by SpdLimited" 23 "reserved" 24 "speed reduce by Tollstation" 25 "ACC cannot active by snow mode" 26 "SteeringAngle is over" 27 "emergency brake suddenly" ;
VAL_ 775 ACC_TimeGapSet 0 "no display" 1 "1.0S" 2 "1.4S" 3 "1.8S" 4 "2.4S" ;
VAL_ 775 ACC_SaftyBelt_Tightened 0 "level0" 1 "level 1" 2 "level 2" 3 "Reserved" ;
VAL_ 775 ACC_SaftyBeltVibrationReq 0 "No Request" 1 "Request" ;
VAL_ 922 LAS_TLAEnable 0 "OFF" 1 "ON" ;
VAL_ 922 LAS_TLAStatus 0 "OFF" 1 "Standby" 2 "Active" 3 "Failure" ;
VAL_ 922 LAS_TLAWarninglevel 0 "no warning" 1 "warning level 1" 2 "warning level 2" 3 "warning level 3" ;
VAL_ 922 LAS_TLAObjectDetection_HostLane 0 "Not Detected" 1 "Detected" ;
VAL_ 922 LAS_TLAObjectColour_HostLane 0 "no display" 1 "Red" 2 "Yellow" 3 "Green" ;
VAL_ 922 LAS_TLAObjectType_HostLane 0 "no display" 1 "Round" 2 "Arrow" 3 "Turn Round" 4 "X-type" 5 "Arrow+Trun" ;
VAL_ 922 LAS_TLAObjectStatus_HostLane 0 "no display" 1 "Lighting" 2 "Flashing" 3 "Disappear" ;
VAL_ 922 LAS_TLAArrowDirection_HostLane 0 "no display" 1 "Forward" 2 "Left" 3 "Forward +Left" 4 "Right" 5 "Forward +Right" 6 "Right+Left" 7 "Left+ Forward +Right" ;
VAL_ 922 LAS_TLAObjectDetection_LeftLane 0 "Not Detected" 1 "Detected" ;
VAL_ 922 LAS_TLAObjectColour_LeftLane 0 "no display" 1 "Red" 2 "Yellow" 3 "Green" ;
VAL_ 922 LAS_TLAObjectStatus_LeftLane 0 "no display" 1 "Lighting" 2 "Flashing" 3 "Disappear" ;
VAL_ 922 LAS_TLAObjectType_LeftLane 0 "no display" 1 "Round" 2 "Arrow" 3 "Turn Round" 4 "X-type" 5 "Arrow+Trun" ;
VAL_ 922 LAS_TLAArrowDirection_LeftLane 0 "no display" 1 "Forward" 2 "Left" 3 "Forward +Left" 4 "Right" 5 "Forward +Right" 6 "Right+Left" 7 "Left+ Forward +Right" ;
VAL_ 922 LAS_TLAObjectDetection_RightLane 0 "Not Detected" 1 "Detected" ;
VAL_ 922 LAS_TLAObjectColour_RightLane 0 "no display" 1 "Red" 2 "Yellow" 3 "Green" ;
VAL_ 922 LAS_TLAObjectStatus_RightLane 0 "no display" 1 "Lighting" 2 "Flashing" 3 "Disappear" ;
VAL_ 922 LAS_TLAObjectType_RightLane 0 "no display" 1 "Round" 2 "Arrow" 3 "Turn Round" 4 "X-type" 5 "Arrow+Trun" ;
VAL_ 922 LAS_TLAArrowDirection_RightLane 0 "no display" 1 "Forward" 2 "Left" 3 "Forward +Left" 4 "Right" 5 "Forward +Right" 6 "Right+Left" 7 "Left+ Forward +Right" ;
VAL_ 922 LAS_OverspeedVisualWarning 0 "No Warning" 1 "Warning" ;
VAL_ 922 LAS_OverspeedSoundWarning 0 "No Warning" 1 "Warning" ;
VAL_ 922 LAS_OverspeedWarningEnableStatus 0 "OFF" 1 "ON" ;
VAL_ 922 LAS_FrontCameraFailureStatus 0 "No Error" 1 "camera blocked" 2 "temporary failure" 3 "permanent failure" ;
VAL_ 922 LAS_FrontCameraCalibrationStatus 0 "Calibration is ok" 1 "Calibration In Process" 2 "Calibration never done" 3 "Calibration Failed" ;
VAL_ 922 LAS_TSRStatus 0 "off" 1 "fusion mode" 2 "vision only mode" 3 "navigation only mode" 4 "reserved" 5 "reserved" 6 "reserved" 7 "Invalid" ;
VAL_ 922 LAS_TSRHostSpdLimit 0 "no speed limit detected" 1 "SL5" 2 "SL10" 3 "SL15" 4 "SL20" 5 "SL25" 6 "SL30" 7 "SL35" 8 "SL40" 9 "SL45" 10 "SL50" 11 "SL55" 12 "SL60" 13 "SL65" 14 "SL70" 15 "SL75" 16 "SL80" 17 "SL85" 18 "SL90" 19 "SL95" 20 "SL100" 21 "SL105" 22 "SL110" 23 "SL115" 24 "SL120" 25 "SL125" 26 "SL130" 27 "SL135" 28 "SL140" 29 "SL145" 30 "SL150" 31 "SL155" 32 "SL160" ;
VAL_ 922 LAS_TSRHostSpdLimitUnits 0 "no display" 1 "unit kph" 2 "unit mph" 3 "reserved" ;
VAL_ 922 LAS_HMAStatus 0 "Off" 1 "Standby" 2 "Active" 3 "Failure" ;
VAL_ 922 LAS_HMALightDistribution 0 "High beam not recommended" 1 "High beam recommended" ;
VAL_ 922 LAS_HMAEnableStatus 0 "off" 1 "on" ;
VAL_ 922 LAS_TSREnable 0 "off" 1 "on" ;
VAL_ 922 LAS_OverspeedSoundWarningEnSt 0 "Off" 1 "On" ;
VAL_ 922 LAS_TSRProhibitionSign 0 "no display" 1 "" 2 "" 3 "" 4 "" 5 "" 6 "" 7 "" 8 "" 9 "" 10 "" 11 "" 12 "" 13 "" 14 "" 15 "" ;
VAL_ 922 LAS_TSRWarningSign 0 "no display" 1 "" 2 "" 3 "" 4 "" 5 "" 6 "" 7 "" 8 "" ;
VAL_ 922 LAS_TSRMandatorySign 0 "no display" 1 "()" 2 "" 3 "" 4 "" 5 "" 6 "" ;
VAL_ 922 LAS_TLACountDownTime_HostLane 0 "no display" ;
VAL_ 922 LAS_TSRLeftLaneSpdLimit 0 "no speed limit detected" 1 "SL5" 2 "SL10" 3 "SL15" 4 "SL20" 5 "SL25" 6 "SL30" 7 "SL35" 8 "SL40" 9 "SL45" 10 "SL50" 11 "SL55" 12 "SL60" 13 "SL65" 14 "SL70" 15 "SL75" 16 "SL80" 17 "SL85" 18 "SL90" 19 "SL95" 20 "SL100" 21 "SL105" 22 "SL110" 23 "SL115" 24 "SL120" 25 "SL125" 26 "SL130" 27 "SL135" 28 "SL140" 29 "SL145" 30 "SL150" 31 "SL155" 32 "SL160" ;
VAL_ 922 LAS_TSRRightLaneSpdLimit 0 "no speed limit detected" 1 "SL5" 2 "SL10" 3 "SL15" 4 "SL20" 5 "SL25" 6 "SL30" 7 "SL35" 8 "SL40" 9 "SL45" 10 "SL50" 11 "SL55" 12 "SL60" 13 "SL65" 14 "SL70" 15 "SL75" 16 "SL80" 17 "SL85" 18 "SL90" 19 "SL95" 20 "SL100" 21 "SL105" 22 "SL110" 23 "SL115" 24 "SL120" 25 "SL125" 26 "SL130" 27 "SL135" 28 "SL140" 29 "SL145" 30 "SL150" 31 "SL155" 32 "SL160" ;
VAL_ 922 LAS_TSRLeftLaneStatus 0 "off" 1 "fusion mode" 2 "vision only mode" 3 "navigation only mode" 4 "reserved" 5 "reserved" 6 "reserved" 7 "Invalid" ;
VAL_ 922 LAS_TSRRightLaneStatus 0 "off" 1 "fusion mode" 2 "vision only mode" 3 "navigation only mode" 4 "reserved" 5 "reserved" 6 "reserved" 7 "Invalid" ;
VAL_ 591 EPS_ConcussAvailabilityStatus 0 "Concuss Availability" 1 "Concuss Active" 2 "EPS Concuss failureEPS" 3 "reserved" ;
VAL_ 591 EPS_IACC_abortreason 0 "NO_DRIVING_INTERUPTION" 1 "DRIVER_RECOVERY(Over ride)" 2 "VEHICLE_SPEED ERROR" 3 "REQUEST ERROR" 4 "DAE_THERMAL_SECURITY" 5 "OTHER_DEFAULT" 6 "MESSAGE FAULT" 7 "RESERVED" ;
VAL_ 591 EPS_TorqSensorStatus 0 "Normal" 1 "Abnormal" ;
VAL_ 591 EpsFaild 0 "No Fail" 1 "Fail" ;
VAL_ 591 EpsSteerModFb 0 "Standar Mode" 1 "Comfort Mode" 2 "Sport Mode" 3 "unknow" ;
VAL_ 382 EPS_LatCtrlActive 0 "Not Actived" 1 "Actived" ;
VAL_ 382 EPS_LatCtrlAvailabilityStatus 0 "not Availability" 1 "Availability" 2 "failure" 3 "reserved" ;
VAL_ 382 EPS_MeasuredTorsionBarTorqValid 0 "" 1 "" ;
VAL_ 384 EpsSasCalSts 0 "Calibrated" 1 "Not Calibrated" ;
VAL_ 384 EpsSasSteerAgVld 0 "Valid" 1 "Invalid" ;
VAL_ 384 EpsSteerAgSensFilr 0 "Valid" 1 "Invalid" ;
VAL_ 706 IB_EPBrequest 0 "NotInitialized" 1 "No Request" 2 "Release brake request" 3 "Lock brake request" ;
VAL_ 706 IB_EPBrequestValid 0 "Valid" 1 "Invalid" ;
VAL_ 706 IbBrkPedlStsGb 0 "" 101 "" ;
VAL_ 706 IbBrkPedlStsGbVld 0 "NotInitialized" 1 "Normal" 2 "Invalid" ;
VAL_ 962 EpbDriverReqParkBrakeDominant 0 "NoDriverDominant" 1 "DriverDominant" ;
VAL_ 962 EpbFailrSts 0 "No error" 1 "Not defined" 2 "Not defined" 3 "error" ;
VAL_ 962 EpbSts 0 "both brakes released" 1 "both brakes applied" 2 "both brakes Releasing" 3 "both brakes Locking" 4 "unknown" ;
VAL_ 962 EspEpbReqAvl 0 "Not available" 1 "available" ;
VAL_ 523 ESP_ABAactive 0 "notactive" 1 "active" ;
VAL_ 523 ESP_ABAavailable 0 "notavailable" 1 "available" ;
VAL_ 523 ESP_AEBAvailable 0 "notavailable" 1 "available" ;
VAL_ 523 ESP_AEBdecActive 0 "notactive" 1 "active" ;
VAL_ 523 ESP_AWBactive 0 "notactive" 1 "active" ;
VAL_ 523 ESP_AWBavailable 0 "notavailable" 1 "available" ;
VAL_ 523 ESP_BrakeForce 0 "nobrakeforce" 1 "havebrakeforce" ;
VAL_ 523 ESP_BrakeOverHeatBrakeDiscTemp 0 "nothigh" 1 "temptoohigh" ;
VAL_ 523 ESP_PrefillActive 0 "notactive" 1 "active" ;
VAL_ 523 ESP_PrefillAvailable 0 "notavailable" 1 "available" ;
VAL_ 523 ESP_QDCACC 0 "noerror" 1 "error" 2 "reserved" 3 "reserved" ;
VAL_ 523 ESP_CDD_Active 0 "notactive" 1 "active" ;
VAL_ 523 ESP_CDD_Available 0 "notavailable" 1 "available" ;
VAL_ 450 EspVehStandstill 0 "Not standstill" 1 "standstill" ;
VAL_ 450 EspLgtAccelVld 0 "Valid" 1 "Invalid " ;
VAL_ 450 WhlSpdRiFrntDir 0 "Forward" 1 "backward" 2 "Standstill" 3 "Invalid" ;
VAL_ 450 WhlSpdLeFrntDir 0 "Forward" 1 "backward" 2 "Standstill" 3 "Invalid" ;
VAL_ 450 WhlSpdRiReDir 0 "Forward" 1 "backward" 2 "Standstill" 3 "Invalid" ;
VAL_ 450 WhlSpdLeReDir 0 "Forward" 1 "backward" 2 "Standstill" 3 "Invalid" ;
VAL_ 450 EspYawAgSpdVld 0 "Valid" 1 "Invalid " ;
VAL_ 450 WhlSpdRiFrntDataVld 0 "Valid" 1 "Invalid " ;
VAL_ 450 WhlSpdLeFrntDataVld 0 "Valid" 1 "Invalid " ;
VAL_ 450 WhlSpdRiReDataVld 0 "Valid" 1 "Invalid " ;
VAL_ 450 WhlSpdLeReDataVld 0 "Valid" 1 "Invalid " ;
VAL_ 450 EspAutoHoldActvSts 0 "Not active" 1 "active" ;
VAL_ 450 EspMstCylBrkPVld 0 "Valid" 1 "Invalid " ;
VAL_ 450 EspVdcActvSts 0 "Not active" 1 "active" ;
VAL_ 450 EspTcsActvSts 0 "Not active" 1 "active" ;
VAL_ 450 EspAbsActv 0 "Not active" 1 "active" ;
VAL_ 450 EspAbsFailr 0 "No error" 1 "Error" ;
VAL_ 450 EspFctOpenSts 0 "Off" 1 "ON" ;
VAL_ 450 EspTcsFailr 0 "No error" 1 "Error" ;
VAL_ 450 EspVehSpdVld 0 "Valid" 1 "Invalid " ;
VAL_ 450 EspReWhlDecTarTqActv 0 "Not active" 1 "active" ;
VAL_ 450 EspReWhlIncTarTqActv 0 "Not active" 1 "active" ;
VAL_ 450 EspActvSts 0 "Not active" 1 "active" ;
VAL_ 450 MbRgnTarWhlQlfr 0 "NotIntialized" 1 "Normal" 2 "Faulty" ;
VAL_ 450 EspLatAccelVld 0 "Valid" 1 "Invalid " ;
VAL_ 466 EspMstCylBrkPVldIB 0 "NotInitialized" 1 "Normal" 2 "Invalid" ;
VAL_ 466 EspVirtMstCylTarBrkPVld 0 "NotInitialized" 1 "Normal" 2 "Invalid" ;
VAL_ 466 EspVehSpdVldIB 0 "NotInitialized" 1 "Normal" 2 "Invalid" ;
VAL_ 442 ACC_LatAngReqActive 0 "not Active" 1 "Active" ;
VAL_ 442 ADS_Reqmode 0 "Parking Runing" 1 "Auto Driving" 2 "ESS runing" 3 "Error" 4 "standby" ;
VAL_ 442 ADS_ErrorStatus 0 "No Error" 1 "Error" ;
VAL_ 978 EpbDriverReqParkBrakeDominant 0 "NoDriverDominant" 1 "DriverDominant" ;
VAL_ 978 EpbFailrSts 0 "No error" 1 "Not defined" 2 "Not defined" 3 "error" ;
VAL_ 978 EpbSts 0 "both brakes released" 1 "both brakes applied" 2 "both brakes Releasing" 3 "both brakes Locking" 4 "unknown" ;
VAL_ 978 EspEpbReqAvl 0 "Not available" 1 "available" ;
VAL_ 676 LCDAR_ELK_oAlert 0 "No warning" 1 "level 1" 2 "level 2" 3 "Reserved" ;
VAL_ 676 LCDAR_ELK_oStatus 0 "OFF()" 1 "Inactive()" 2 "Active" 3 "Failure" ;
VAL_ 676 LCDAR_Left_ELK_oAlert 0 "No warning" 1 "level 1" 2 "level 2" 3 "Reserved" ;
VAL_ 676 LCDAR_Left_RCTAAlert 0 "No RCTA warning" 1 "RCTA warning Level1" 2 "RCTA warning Level2" 3 "RCTA warning Level3" ;
VAL_ 676 LCDAR_RCTBActive 0 "not Active" 1 "Active." ;
VAL_ 676 LCDAR_RCTBEnable 0 "off" 1 "on" ;
VAL_ 676 LCDAR_SystemStatus 0 "Reserved" 1 "StartUp" 2 "Running" 3 "Blocked" 4 "Calibration" 5 "ShutDown" 6 "Hot" 7 "Failure" ;
VAL_ 906 VcuCrsDstSwtSts 0 "" 1 "" 2 "" 3 "Error" ;
VAL_ 906 VcuCrsResuSwtSts 0 "" 1 "" 2 "" 3 "Error" ;
VAL_ 906 VcuCrsSetSwtSts 0 "" 1 "" 2 "" 3 "Error" ;
VAL_ 906 VcuCrsSwtDiagInfo 0 "Reset" 1 "Variants of wrong information()" 2 "voltage is higher than 16V(16V)" 3 "voltage is lower than 9V(9V)" 7 "invalid" ;
VAL_ 957 HU_CSLAEnable 0 "OFF" 1 "All Speed-Limit" 2 "Road Camera" 3 "invalid" ;
VAL_ 957 HU_ELKEnable 0 "Inactive" 1 "OFF" 2 "ON" 3 "Reserved" ;
VAL_ 957 HU_TLAEnable 0 "Inactive" 1 "OFF" 2 "ON" 3 "Reserved" ;
VAL_ 888 ACC_LaneEquationStatus 0 "no display" 1 "Left Lane" 2 "Right Lane" 3 "reserved" ;
VAL_ 685 LCDAL_SystemStatus 0 "Reserved" 1 "StartUp" 2 "Running" 3 "Blocked" 4 "Calibration" 5 "ShutDown" 6 "Hot" 7 "Failure" ;
VAL_ 701 RRC_OBJ1_Type 0 "Not Detected" 1 "car" 2 "truck" 3 "bicycle/motorbike" 4 "cyclist" ;
VAL_ 701 RRC_OBJ1_Location 0 "unknown" 1 "Left Lane" 2 "Right  Lane" 3 "Ego Lane" ;
VAL_ 701 RRC_OBJ1_Measured 0 "unknown" 1 "Measured" 2 "Predicted" 3 "Reserved" ;
VAL_ 701 RRC_OBJ2_Type 0 "Not Detected" 1 "car" 2 "truck" 3 "bicycle/motorbike" 4 "cyclist" ;
VAL_ 701 RRC_OBJ2_Location 0 "unknown" 1 "Left Lane" 2 "Right  Lane" 3 "Ego Lane" ;
VAL_ 701 RRC_OBJ2_Measured 0 "unknown" 1 "Measured" 2 "Predicted" 3 "Reserved" ;
VAL_ 701 RRC_OBJ3_Type 0 "Not Detected" 1 "car" 2 "truck" 3 "bicycle/motorbike" 4 "cyclist" ;
VAL_ 701 RRC_OBJ3_Location 0 "unknown" 1 "Left Lane" 2 "Right  Lane" 3 "Ego Lane" ;
VAL_ 701 RRC_OBJ3_Measured 0 "unknown" 1 "Measured" 2 "Predicted" 3 "Reserved" ;
VAL_ 701 RRC_OBJ4_Type 0 "Not Detected" 1 "car" 2 "truck" 3 "bicycle/motorbike" 4 "cyclist" ;
VAL_ 701 RRC_OBJ4_Location 0 "unknown" 1 "Left Lane" 2 "Right  Lane" 3 "Ego Lane" ;
VAL_ 701 RRC_OBJ4_Measured 0 "unknown" 1 "Measured" 2 "Predicted" 3 "Reserved" ;
VAL_ 712 RRC_OBJ5_Type 0 "Not Detected" 1 "car" 2 "truck" 3 "bicycle/motorbike" 4 "cyclist" ;
VAL_ 712 RRC_OBJ5_Location 0 "unknown" 1 "Left Lane" 2 "Right  Lane" 3 "Ego Lane" ;
VAL_ 712 RRC_OBJ5_Measured 0 "unknown" 1 "Measured" 2 "Predicted" 3 "Reserved" ;
VAL_ 712 RRC_OBJ10_Type 0 "Not Detected" 1 "car" 2 "truck" 3 "bicycle/motorbike" 4 "cyclist" ;
VAL_ 712 RRC_OBJ10_Location 0 "unknown" 1 "Left Lane" 2 "Right  Lane" 3 "Ego Lane" ;
VAL_ 712 RRC_OBJ10_Measured 0 "unknown" 1 "Measured" 2 "Predicted" 3 "Reserved" ;
VAL_ 712 RRC_TiOut 0 "no timeout" 1 "timeout" ;
VAL_ 703 RRC_OBJ6_Type 0 "Not Detected" 1 "car" 2 "truck" 3 "bicycle/motorbike" 4 "cyclist" ;
VAL_ 703 RRC_OBJ6_Location 0 "unknown" 1 "Left Lane" 2 "Right  Lane" 3 "Ego Lane" ;
VAL_ 703 RRC_OBJ6_Measured 0 "unknown" 1 "Measured" 2 "Predicted" 3 "Reserved" ;
VAL_ 703 RRC_OBJ7_Type 0 "Not Detected" 1 "car" 2 "truck" 3 "bicycle/motorbike" 4 "cyclist" ;
VAL_ 703 RRC_OBJ7_Location 0 "unknown" 1 "Left Lane" 2 "Right  Lane" 3 "Ego Lane" ;
VAL_ 703 RRC_OBJ7_Measured 0 "unknown" 1 "Measured" 2 "Predicted" 3 "Reserved" ;
VAL_ 703 RRC_OBJ8_Type 0 "Not Detected" 1 "car" 2 "truck" 3 "bicycle/motorbike" 4 "cyclist" ;
VAL_ 703 RRC_OBJ8_Location 0 "unknown" 1 "Left Lane" 2 "Right  Lane" 3 "Ego Lane" ;
VAL_ 703 RRC_OBJ8_Measured 0 "unknown" 1 "Measured" 2 "Predicted" 3 "Reserved" ;
VAL_ 703 RRC_OBJ9_Type 0 "Not Detected" 1 "car" 2 "truck" 3 "bicycle/motorbike" 4 "cyclist" ;
VAL_ 703 RRC_OBJ9_Location 0 "unknown" 1 "Left Lane" 2 "Right  Lane" 3 "Ego Lane" ;
VAL_ 703 RRC_OBJ9_Measured 0 "unknown" 1 "Measured" 2 "Predicted" 3 "Reserved" ;
VAL_ 1468 LasHwVers0 72 "H" ;
VAL_ 1468 LasHwVers1 87 "W" ;
VAL_ 1468 LasHwVers2 48 "0" 49 "1" 50 "2" 51 "3" 52 "4" 53 "5" 54 "6" 55 "7" 56 "8" 57 "9" 65 "A" 66 "B" 67 "C" 68 "D" 69 "E" 70 "F" 71 "G" 72 "H" 73 "I" 74 "J" 75 "K" 76 "L" 77 "M" 78 "N" 79 "O" 80 "P" 81 "Q" 82 "R" 83 "S" 84 "T" 85 "U" 86 "V" 87 "W" 88 "X" 89 "Y" 90 "Z" ;
VAL_ 1468 LasHwVers3 46 "." ;
VAL_ 1468 LasHwVers4 48 "0" 49 "1" 50 "2" 51 "3" 52 "4" 53 "5" 54 "6" 55 "7" 56 "8" 57 "9" 65 "A" 66 "B" 67 "C" 68 "D" 69 "E" 70 "F" 71 "G" 72 "H" 73 "I" 74 "J" 75 "K" 76 "L" 77 "M" 78 "N" 79 "O" 80 "P" 81 "Q" 82 "R" 83 "S" 84 "T" 85 "U" 86 "V" 87 "W" 88 "X" 89 "Y" 90 "Z" ;
VAL_ 1468 LasHwVers5 46 "." ;
VAL_ 1468 LasHwVers6 48 "0" 49 "1" 50 "2" 51 "3" 52 "4" 53 "5" 54 "6" 55 "7" 56 "8" 57 "9" 65 "A" 66 "B" 67 "C" 68 "D" 69 "E" 70 "F" 71 "G" 72 "H" 73 "I" 74 "J" 75 "K" 76 "L" 77 "M" 78 "N" 79 "O" 80 "P" 81 "Q" 82 "R" 83 "S" 84 "T" 85 "U" 86 "V" 87 "W" 88 "X" 89 "Y" 90 "Z" ;
VAL_ 1468 LasSwVers0 83 "S" ;
VAL_ 1468 LasSwVers1 87 "W" ;
VAL_ 1468 LasSwVers2 48 "0" 49 "1" 50 "2" 51 "3" 52 "4" 53 "5" 54 "6" 55 "7" 56 "8" 57 "9" 65 "A" 66 "B" 67 "C" 68 "D" 69 "E" 70 "F" 71 "G" 72 "H" 73 "I" 74 "J" 75 "K" 76 "L" 77 "M" 78 "N" 79 "O" 80 "P" 81 "Q" 82 "R" 83 "S" 84 "T" 85 "U" 86 "V" 87 "W" 88 "X" 89 "Y" 90 "Z" ;
VAL_ 1468 LasSwVers3 46 "." ;
VAL_ 1468 LasSwVers4 48 "0" 49 "1" 50 "2" 51 "3" 52 "4" 53 "5" 54 "6" 55 "7" 56 "8" 57 "9" 65 "A" 66 "B" 67 "C" 68 "D" 69 "E" 70 "F" 71 "G" 72 "H" 73 "I" 74 "J" 75 "K" 76 "L" 77 "M" 78 "N" 79 "O" 80 "P" 81 "Q" 82 "R" 83 "S" 84 "T" 85 "U" 86 "V" 87 "W" 88 "X" 89 "Y" 90 "Z" ;
VAL_ 1468 LasSwVers5 46 "." ;
VAL_ 1468 LasSwVers6 48 "0" 49 "1" 50 "2" 51 "3" 52 "4" 53 "5" 54 "6" 55 "7" 56 "8" 57 "9" 65 "A" 66 "B" 67 "C" 68 "D" 69 "E" 70 "F" 71 "G" 72 "H" 73 "I" 74 "J" 75 "K" 76 "L" 77 "M" 78 "N" 79 "O" 80 "P" 81 "Q" 82 "R" 83 "S" 84 "T" 85 "U" 86 "V" 87 "W" 88 "X" 89 "Y" 90 "Z" ;
